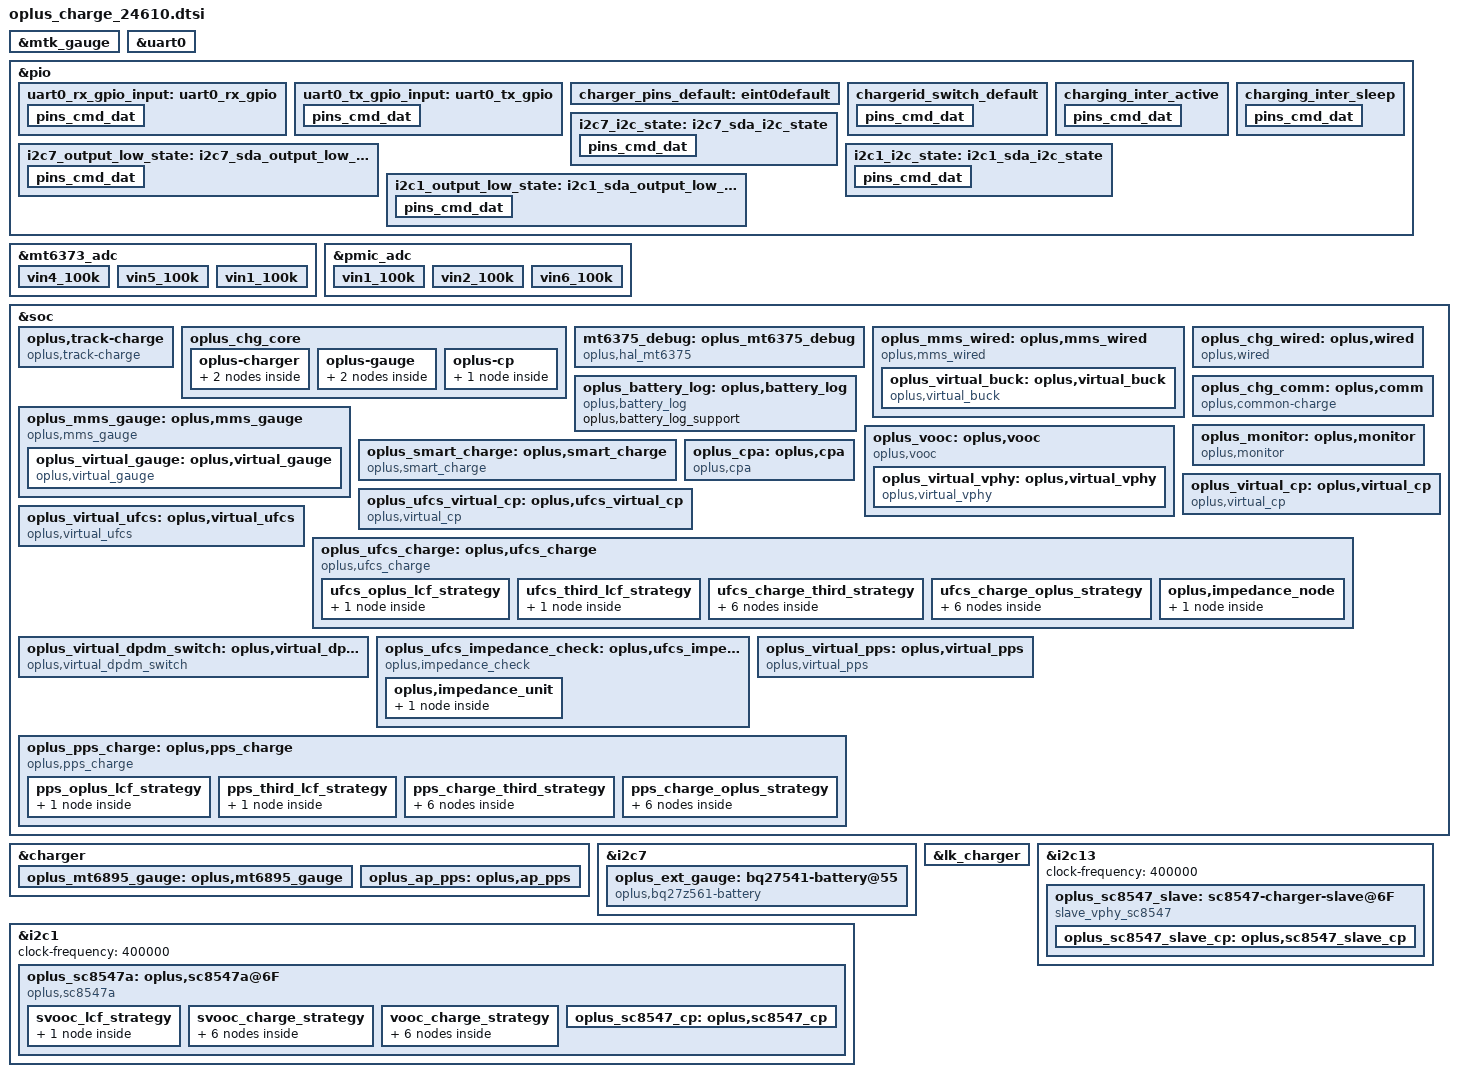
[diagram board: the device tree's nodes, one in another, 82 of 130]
// SPDX-License-Identifier: GPL-2.0-only
/*
* Copyright (C) 2021-2020 Oplus. All rights reserved.
*/
#include <dt-bindings/iio/mt635x-auxadc.h>
#include <dt-bindings/pinctrl/mt6373-pinfunc.h>
#include <dt-bindings/pinctrl/mt65xx.h>
//#include "oplus_charge_24610.h"
#include "oplus_chg.h"

/* charge start */
//&regulator_vibrator{
//	status = "disabled";
//};

&mtk_gauge {
	disable-mtkbattery = <(1)>;
	charger = <&mt6375_chg>;
};

&uart0 {
	pinctrl-names = "uart0_rx_gpio", "uart0_tx_gpio";
	pinctrl-0 = <&uart0_rx_gpio_input>;
	pinctrl-1 = <&uart0_tx_gpio_input>;
	status = "okay";

	txpin = <203>;
	rxpin = <204>;
};

&pio {
	uart0_rx_gpio_input: uart0_rx_gpio {
		pins_cmd_dat {
			pinmux = <PINMUX_GPIO204__FUNC_GPIO204>;
			input-enable;
			bias-disable;
		};
	};

	uart0_tx_gpio_input: uart0_tx_gpio {
		pins_cmd_dat {
			pinmux = <PINMUX_GPIO203__FUNC_GPIO203>;
			input-enable;
			bias-disable;
		};
	};
};

/* mt6373_adc is defined in mt6373.dtsi */
&mt6373_adc {
	vin4_100k {
		channel = <AUXADC_VIN4>;
		pures = <ADC_PURES_100K>;
	};
	vin5_100k {
		channel = <AUXADC_VIN5>;
		pures = <ADC_PURES_100K>;
	};
	vin1_100k {
		channel = <AUXADC_VIN1>;
		pures = <ADC_PURES_100K>;
	};
};

/* pmic_adc is defined in mt6363.dtsi */
&pmic_adc {
	vin1_100k {
		channel = <AUXADC_VIN1>;
		pures = <ADC_PURES_100K>;
	};
	vin2_100k {
		channel = <AUXADC_VIN2>;
		pures = <ADC_PURES_100K>;
	};
	vin6_100k {
		channel = <AUXADC_VIN6>;
		pures = <ADC_PURES_100K>;
	};
};

&soc {
	oplus,track-charge {
		compatible = "oplus,track-charge";
		track,fast_chg_break_t_thd = <1400>;
		track,general_chg_break_t_thd = <300>;
		track,voocphy_type = <TRACK_AP_SINGLE_CP_VOOCPHY>;
		track,wired_max_power = <100000>;
		track,wired_fast_chg_scheme = <0>;
	};

};

&pio {
	charger_pins_default: eint0default {
	};

	chargerid_switch_default: chargerid_switch_default {
		pins_cmd_dat {
			pinmux = <PINMUX_GPIO81__FUNC_GPIO81>;
			bias-disable;
		};
	};

	charging_inter_active: charging_inter_active {
		pins_cmd_dat {
			pinmux = <PINMUX_GPIO83__FUNC_GPIO83>;
			input-enable;
			bias-pull-up;
		};
	};

	charging_inter_sleep: charging_inter_sleep {
		pins_cmd_dat {
			pinmux = <PINMUX_GPIO83__FUNC_GPIO83>;
			input-enable;
			bias-pull-up;
		};
	};
};

&soc {
	oplus_chg_core {
		oplus,chg_framework_v2;
		oplus,smart_charging_screenoff;
		oplus,chg_spec_version = <OPLUS_CHG_SPEC_VER_V3P7>;

		oplus-charger {
			mtk_6895_groups: oplus,mtk_6895-groups {
				functions = <
					OPLUS_IC_FUNC_INIT
					OPLUS_IC_FUNC_EXIT
					OPLUS_IC_FUNC_REG_DUMP
					OPLUS_IC_FUNC_SMT_TEST
					OPLUS_IC_FUNC_BUCK_INPUT_PRESENT
					OPLUS_IC_FUNC_BUCK_INPUT_SUSPEND
					OPLUS_IC_FUNC_BUCK_INPUT_IS_SUSPEND
					OPLUS_IC_FUNC_BUCK_OUTPUT_SUSPEND
					OPLUS_IC_FUNC_BUCK_OUTPUT_IS_SUSPEND
					OPLUS_IC_FUNC_BUCK_SET_ICL
					OPLUS_IC_FUNC_BUCK_GET_ICL
					OPLUS_IC_FUNC_BUCK_SET_FCC
					OPLUS_IC_FUNC_BUCK_SET_FV
					OPLUS_IC_FUNC_BUCK_SET_ITERM
					OPLUS_IC_FUNC_BUCK_GET_INPUT_CURR
					OPLUS_IC_FUNC_BUCK_GET_INPUT_VOL
					OPLUS_IC_FUNC_OTG_BOOST_ENABLE
					OPLUS_IC_FUNC_BUCK_GET_CC_ORIENTATION
					OPLUS_IC_FUNC_BUCK_GET_CHARGER_TYPE
					OPLUS_IC_FUNC_BUCK_RERUN_BC12
					OPLUS_IC_FUNC_BUCK_QC_DETECT_ENABLE
					OPLUS_IC_FUNC_BUCK_SET_QC_CONFIG
					OPLUS_IC_FUNC_BUCK_SET_PD_CONFIG
					OPLUS_IC_FUNC_GET_SHUTDOWN_SOC
					OPLUS_IC_FUNC_BACKUP_SOC
					OPLUS_IC_FUNC_GET_TYPEC_MODE
					OPLUS_IC_FUNC_SET_TYPEC_MODE
					OPLUS_IC_FUNC_GET_TYPEC_ROLE
					OPLUS_IC_FUNC_GET_OTG_ENABLE
					OPLUS_IC_FUNC_BUCK_GET_HW_DETECT
					OPLUS_IC_FUNC_SET_USB_DISCHG_ENABLE
					OPLUS_IC_FUNC_GET_USB_DISCHG_STATUS
					OPLUS_IC_FUNC_IS_OPLUS_SVID
					OPLUS_IC_FUNC_BUCK_GET_USB_BTB_TEMP
					OPLUS_IC_FUNC_BUCK_GET_BATT_BTB_TEMP
					OPLUS_IC_FUNC_BUCK_SHIPMODE_ENABLE
					OPLUS_IC_FUNC_BUCK_SET_AICL_POINT
					OPLUS_IC_FUNC_SET_OTG_BOOST_CURR_LIMIT
					OPLUS_IC_FUNC_BUCK_GET_FV
					OPLUS_IC_FUNC_BUCK_GET_TYPEC_STATE
				>;
				virqs = <
					OPLUS_IC_VIRQ_ERR
					OPLUS_IC_VIRQ_CC_DETECT
					OPLUS_IC_VIRQ_PLUGIN
					OPLUS_IC_VIRQ_CC_CHANGED
					OPLUS_IC_VIRQ_CHG_TYPE_CHANGE
					OPLUS_IC_VIRQ_OTG_ENABLE
					OPLUS_IC_VIRQ_SVID
					OPLUS_IC_VIRQ_TYPEC_STATE
				>;
			};


			mt6375_debug_groups: oplus,mt6375_debug_groups {
				functions = <
					OPLUS_IC_FUNC_INIT
					OPLUS_IC_FUNC_EXIT
				>;
				virqs = <
					OPLUS_IC_VIRQ_ERR
				>;
			};
		};

		oplus-gauge {
			bq27541_groups: oplus,bq27541_groups {
				functions = <
					OPLUS_IC_FUNC_INIT
					OPLUS_IC_FUNC_EXIT
					OPLUS_IC_FUNC_REG_DUMP
					OPLUS_IC_FUNC_SMT_TEST
					OPLUS_IC_FUNC_GAUGE_GET_BATT_VOL
					OPLUS_IC_FUNC_GAUGE_GET_BATT_MAX
					OPLUS_IC_FUNC_GAUGE_GET_BATT_MIN
					OPLUS_IC_FUNC_GAUGE_GET_BATT_CURR
					OPLUS_IC_FUNC_GAUGE_GET_BATT_TEMP
					OPLUS_IC_FUNC_GAUGE_GET_BATT_SOC
					OPLUS_IC_FUNC_GAUGE_GET_BATT_FCC
					OPLUS_IC_FUNC_GAUGE_GET_BATT_CC
					OPLUS_IC_FUNC_GAUGE_GET_BATT_RM
					OPLUS_IC_FUNC_GAUGE_GET_BATT_SOH
					OPLUS_IC_FUNC_GAUGE_GET_BATT_AUTH
					OPLUS_IC_FUNC_GAUGE_GET_BATT_HMAC
					OPLUS_IC_FUNC_GAUGE_SET_BATT_FULL
					OPLUS_IC_FUNC_GAUGE_UPDATE_DOD0
					OPLUS_IC_FUNC_GAUGE_UPDATE_SOC_SMOOTH
					OPLUS_IC_FUNC_GAUGE_GET_CB_STATUS
					OPLUS_IC_FUNC_GAUGE_GET_BATT_NUM
					OPLUS_IC_FUNC_GAUGE_GET_DEVICE_TYPE
					OPLUS_IC_FUNC_GAUGE_GET_DEVICE_TYPE_FOR_VOOC
					OPLUS_IC_FUNC_GAUGE_GET_BATT_FCC
					OPLUS_IC_FUNC_GAUGE_GET_BATT_FC
					OPLUS_IC_FUNC_GAUGE_GET_BATT_QM
					OPLUS_IC_FUNC_GAUGE_GET_BATT_PD
					OPLUS_IC_FUNC_GAUGE_GET_BATT_RCU
					OPLUS_IC_FUNC_GAUGE_GET_BATT_RCF
					OPLUS_IC_FUNC_GAUGE_GET_BATT_FCU
					OPLUS_IC_FUNC_GAUGE_GET_BATT_FCF
					OPLUS_IC_FUNC_GAUGE_GET_BATT_SOU
					OPLUS_IC_FUNC_GAUGE_GET_BATT_DO0
					OPLUS_IC_FUNC_GAUGE_GET_BATT_DOE
					OPLUS_IC_FUNC_GAUGE_GET_BATT_TRM
					OPLUS_IC_FUNC_GAUGE_GET_BATT_PC
					OPLUS_IC_FUNC_GAUGE_GET_BATT_QS
					OPLUS_IC_FUNC_GAUGE_IS_SUSPEND
					OPLUS_IC_FUNC_GAUGE_GET_BCC_PARMS
					OPLUS_IC_FUNC_GAUGE_FASTCHG_UPDATE_BCC_PARMS
					OPLUS_IC_FUNC_GAUGE_GET_PREV_BCC_PARMS
					OPLUS_IC_FUNC_GAUGE_SET_BCC_PARMS
					OPLUS_IC_FUNC_GAUGE_SET_PROTECT_CHECK
					OPLUS_IC_FUNC_GAUGE_GET_AFI_UPDATE_DONE
					OPLUS_IC_FUNC_GAUGE_CHECK_RESET
					OPLUS_IC_FUNC_GAUGE_SET_RESET
					OPLUS_IC_FUNC_GAUGE_GET_DEVICE_TYPE_FOR_BCC
					OPLUS_IC_FUNC_GAUGE_GET_DOD0
					OPLUS_IC_FUNC_GAUGE_GET_DOD0_PASSED_Q
					OPLUS_IC_FUNC_GAUGE_GET_QMAX
					OPLUS_IC_FUNC_GAUGE_GET_QMAX_PASSED_Q
					OPLUS_IC_FUNC_GAUGE_GET_REG_INFO
					OPLUS_IC_FUNC_GAUGE_GET_CALIB_TIME
				>;
				virqs = <
					OPLUS_IC_VIRQ_ERR
					OPLUS_IC_VIRQ_OFFLINE
					OPLUS_IC_VIRQ_RESUME
				>;
			};

			mt6895_gauge_groups: oplus,mt6895_gauge_groups {
				functions = <
					OPLUS_IC_FUNC_INIT
					OPLUS_IC_FUNC_EXIT
					OPLUS_IC_FUNC_GAUGE_GET_SUBBOARD_TEMP
				>;
				virqs = <
					OPLUS_IC_VIRQ_ERR
				>;
			};
		};

		oplus-cp {
			sc8547_cp_groups: oplus,cp_groups {
			functions = <
					OPLUS_IC_FUNC_INIT
					OPLUS_IC_FUNC_EXIT
					OPLUS_IC_FUNC_REG_DUMP
					OPLUS_IC_FUNC_SMT_TEST
					OPLUS_IC_FUNC_CP_ENABLE
					OPLUS_IC_FUNC_CP_HW_INTI
					OPLUS_IC_FUNC_CP_SET_WORK_START
					OPLUS_IC_FUNC_CP_CHECK_WORK_MODE_SUPPORT
					OPLUS_IC_FUNC_CP_SET_WORK_MODE
					OPLUS_IC_FUNC_CP_GET_WORK_MODE
					OPLUS_IC_FUNC_CP_GET_VIN
					OPLUS_IC_FUNC_CP_GET_IIN
					OPLUS_IC_FUNC_CP_SET_IIN
					OPLUS_IC_FUNC_CP_GET_VOUT
					OPLUS_IC_FUNC_CP_GET_IOUT
					OPLUS_IC_FUNC_CP_GET_VAC
					OPLUS_IC_FUNC_CP_GET_WORK_STATUS
					OPLUS_IC_FUNC_CP_SET_ADC_ENABLE
					OPLUS_IC_FUNC_CP_WATCHDOG_ENABLE
				>;
				virqs = <
					OPLUS_IC_VIRQ_ERR
					OPLUS_IC_VIRQ_ONLINE
					OPLUS_IC_VIRQ_OFFLINE
				>;
			};
		};
	};
};

&soc {
	mt6375_debug: oplus_mt6375_debug {
		status = "okay";
		compatible = "oplus,hal_mt6375";

		oplus,tcpc_name = "type_c_port0";

		oplus,ic_type = <OPLUS_CHG_IC_BUCK>;
		oplus,ic_index = <2>;
	};
};

&charger {
	io-channels = <&mt6373_adc AUXADC_VIN1>,
			<&pmic_adc (ADC_PURES_100K_MASK | AUXADC_VIN1)>,
			<&pmic_adc (ADC_PURES_100K_MASK | AUXADC_VIN2)>,
			<&pmic_adc (ADC_PURES_100K_MASK | AUXADC_VIN6)>;
	io-channel-names = "auxadc5-chargeric_temp", "auxadc1-ntc_sub_bat_tem",
			   "auxadc5_batt_btb_temp", "auxadc6_usb_btb_temp";

	pinctrl-names = "default";
	pinctrl-0 = <&charger_pins_default>;
	oplus,support_ntc_01c_precision;
	oplus,support_subboard_ntc;
	max_charger_voltage = <15000000>;

	/* usbtemp dischg use pmic regulator to set vbus down */
	oplus,support_usbtemp_dischg_reg_configurable;
	oplus,usbtemp_dischg_reg_addr = <0x989>;
	oplus,usbtemp_dischg_reg_mask = <0x7>;
	oplus,usbtemp_dischg_enable = <0x2>;
	oplus,usbtemp_dischg_disable = <0x0>;

	oplus,ic_type = <OPLUS_CHG_IC_BUCK>;
	oplus,ic_index = <0>;

	oplus_mt6895_gauge: oplus,mt6895_gauge {
		oplus,ic_type = <OPLUS_CHG_IC_GAUGE>;
		oplus,ic_index = <1>;
	};
};
&i2c7 {
	status = "okay";
	clock-frequency = <100000>;

	oplus_ext_gauge: bq27541-battery@55 {
		status = "okay";
		compatible = "oplus,bq27z561-battery";
		reg = <0x55>;
		qcom,modify-soc-smooth;
		qcom,modify-soc-calibration;
		oplus,support_extern_cmd;
		oplus,batt_num = <1>;
		oplus,ic_type = <OPLUS_CHG_IC_GAUGE>;
		oplus,ic_index = <0>;
	};
};
&lk_charger {
	single_batt_external_gauge_support;
	is_support_mt6375;
	support_battery_type = <8>;
	support_tuv_authentication;
	support_sdp_screenoff;
	use_extern_gauge;
	high-temp-scheme;
	sub_board_temp_support;
	over_high_temp_thr = <60>;
	sub_board_adc_channel = <18>; /* AUXADC_VIN1 */
	sub_board_adc_pull_up_voltage = <1840>;

	support_quickboot_charge;

	/* mt6989 start */
	led-brightness = <102>;
	/* mt6989, such as max_charger_voltage to max-charger-voltage */
	max-charger-voltage = <15000000>;
	boot-battery-voltage = <3350000>;
	usb-charger-current = <500000>;
	ac-charger-current = <2050000>;
	ac-charger-input-current = <1500000>;
	non-std-ac-charger-current = <750000>;
	charging-host-charger-current = <1500000>;
	ta-ac-charger-current = <1500000>;
	pd-charger-current = <500000>;
	/* mt6989 end */
};

&i2c7 {
	pinctrl-names = "i2c-state", "output-low-state";
	pinctrl-0 = <&i2c7_i2c_state>;
	pinctrl-1 = <&i2c7_output_low_state>;
};
&pio {
	i2c7_i2c_state: i2c7_sda_i2c_state {
		pins_cmd_dat {
			pinmux = <PINMUX_GPIO120__FUNC_SCL7>,
			<PINMUX_GPIO121__FUNC_SDA7>;
			bias-pull-up;
		};
	};
	i2c7_output_low_state: i2c7_sda_output_low_state {
		pins_cmd_dat {
			pinmux = <PINMUX_GPIO120__FUNC_GPIO120>,
			<PINMUX_GPIO121__FUNC_GPIO121>;
			output-low;
		};
	};
};

&soc {
	oplus_mms_wired: oplus,mms_wired {
		compatible = "oplus,mms_wired";
		oplus,buck_ic = <&oplus_virtual_buck>;
		oplus,voocphy_ic = <&oplus_virtual_vphy>;

		oplus,adc_info_name = "100k_1840mv";
		oplus_spec,usbtemp_batttemp_gap = <12>;

		/* support for V2.0 usbtemp protect. */
		oplus,support_usbtemp_protect_v2;
		oplus_spec,usbtemp_batt_temp_low = <50>;
		oplus_spec,usbtemp_batt_temp_high = <50>;
		oplus_spec,usbtemp_batt_temp_over_hot = <60>;
		oplus_spec,usbtemp_ntc_temp_low = <57>;
		oplus_spec,usbtemp_ntc_temp_high = <69>;
		oplus_spec,usbtemp_temp_gap_low_with_batt_temp = <7>;
		oplus_spec,usbtemp_temp_gap_with_batt_temp_in_over_hot = <15>;
		oplus_spec,usbtemp_temp_gap_high_with_batt_temp = <12>;
		oplus_spec,usbtemp_temp_gap_low_without_batt_temp = <12>;
		oplus_spec,usbtemp_temp_gap_high_without_batt_temp = <24>;
		oplus_spec.usbtemp_rise_fast_temp_low = <3>;
		oplus_spec.usbtemp_rise_fast_temp_high = <3>;
		oplus_spec.usbtemp_rise_fast_temp_count_low = <30>;
		oplus_spec.usbtemp_rise_fast_temp_count_high = <20>;
		oplus_spec,usbtemp_cool_down_ntc_low = <54>;
		oplus_spec,usbtemp_cool_down_ntc_high = <65>;
		oplus_spec,usbtemp_cool_down_gap_low = <12>;
		oplus_spec,usbtemp_cool_down_gap_high = <20>;
		oplus_spec,usbtemp_cool_down_recover_ntc_low = <48>;
		oplus_spec,usbtemp_cool_down_recover_ntc_high = <60>;
		oplus_spec,usbtemp_cool_down_recover_gap_low = <6>;
		oplus_spec,usbtemp_cool_down_recover_gap_high = <15>;
		oplus_spec,usbtemp_otg_cc_boot_current_limit = <1300000>;

		oplus_virtual_buck: oplus,virtual_buck {
			compatible = "oplus,virtual_buck";
			oplus,buck_ic = <&charger &mt6375_debug>;
			oplus,buck_ic_index = <0 1>;
			oplus,buck_ic_current_ratio = <100 0>;
			oplus,buck_ic_connect = <OPLUS_CHG_IC_CONNECT_PARALLEL>;
			oplus,main_charger = <0>;
			oplus,buck_ic_func_group = <&mtk_6895_groups &mt6375_debug_groups>;

			oplus,ic_type = <OPLUS_CHG_IC_VIRTUAL_BUCK>;
			oplus,ic_index = <0>;

			io-channels = <&mt6373_adc AUXADC_VIN4>, <&mt6373_adc AUXADC_VIN5>;
			io-channel-names = "usb_temp_adc_l", "usb_temp_adc_r";

			oplus,uart_tx-gpio = <&pio 203 0x00>;
			oplus,uart_rx-gpio = <&pio 204 0x00>;
		};
	};

	oplus_mms_gauge: oplus,mms_gauge {
		compatible = "oplus,mms_gauge";
		oplus,gauge_ic = <&oplus_virtual_gauge>;
		oplus,topic-update-interval = <10000>;
		oplus,support_subboard_ntc;

		oplus_virtual_gauge: oplus,virtual_gauge {
			compatible = "oplus,virtual_gauge";
			oplus,gauge_ic = <&oplus_ext_gauge &oplus_mt6895_gauge>;
			oplus,gauge_ic_index = <0 1>;
			oplus,gauge_ic_func_group = <&bq27541_groups &mt6895_gauge_groups>;
			oplus,batt_capacity_mah = <7000>;
			oplus,ic_type = <OPLUS_CHG_IC_VIRTUAL_GAUGE>;
			oplus,ic_index = <0>;
		};
	};
};

&soc {
	oplus_battery_log: oplus,battery_log {
		compatible = "oplus,battery_log";

		oplus,battery_log_support;
	};

	oplus_chg_wired: oplus,wired {
		compatible = "oplus,wired";

		oplus,vooc-support;

		oplus_spec,vbatt_pdqc_to_5v_thr = <4500>;
		oplus_spec,vbatt_pdqc_to_9v_thr = <4500>;
		oplus_spec,pd-iclmax-ma = <2000>;
		oplus_spec,qc-iclmax-ma = <2000>;
		oplus_spec,non-standard-ibatmax-ma = <500>;
		oplus_spec,input-power-mw = <
			2500		/* OPLUS_WIRED_CHG_MODE_UNKNOWN */
			2500		/* OPLUS_WIRED_CHG_MODE_SDP */
			7500		/* OPLUS_WIRED_CHG_MODE_CDP */
			10000		/* OPLUS_WIRED_CHG_MODE_DCP */
			15000		/* OPLUS_WIRED_CHG_MODE_VOOC */
			13500		/* OPLUS_WIRED_CHG_MODE_QC */
			13500		/* OPLUS_WIRED_CHG_MODE_PD */
		>;
		oplus_spec,led_on-fccmax-ma = <0 1850 3083 3300 3300 3300 3300 1000 0>;
		oplus_spec,fccmax-ma-lv = <
			0 1850 2200 2200 2200 2200 2200 2200 0	/* OPLUS_WIRED_CHG_MODE_UNKNOWN */
			0 600  600  600  600  600  600  600  0	/* OPLUS_WIRED_CHG_MODE_SDP */
			0 1600 1600 1600 1600 1600 1600 1600 0	/* OPLUS_WIRED_CHG_MODE_CDP */
			0 1850 2200 2200 2200 2200 2200 2200 0	/* OPLUS_WIRED_CHG_MODE_DCP */
			0 1850 2200 2200 2200 2200 2200 2200 0	/* OPLUS_WIRED_CHG_MODE_VOOC */
			0 1850 3083 3300 3300 3300 3300 3300 0	/* OPLUS_WIRED_CHG_MODE_QC */
			0 1850 3083 3300 3300 3300 3300 3300 0	/* OPLUS_WIRED_CHG_MODE_PD */
		>;
		oplus_spec,fccmax-ma-hv = <
			0 617  1233 1600 1600 1600 1600 1600 0	/* OPLUS_WIRED_CHG_MODE_UNKNOWN */
			0 600  600  600  600  600  600  600  0	/* OPLUS_WIRED_CHG_MODE_SDP */
			0 617  1233 1600 1600 1600 1600 1600 0	/* OPLUS_WIRED_CHG_MODE_CDP */
			0 617  1233 1850 2200 2200 2200 2200 0	/* OPLUS_WIRED_CHG_MODE_DCP */
			0 617  1233 1850 2200 2200 2200 2200 0	/* OPLUS_WIRED_CHG_MODE_VOOC */
			0 617  1233 1850 3083 3300 3300 3300 0	/* OPLUS_WIRED_CHG_MODE_QC */
			0 617  1233 1850 3083 3300 3300 3300 0	/* OPLUS_WIRED_CHG_MODE_PD */
		>;
                oplus_spec,cool_down_sale_pdqc_vol_mv = <5000>;
                oplus_spec,cool_down_sale_pdqc_curr_ma = <1200>;
                oplus_spec,cool_down_pdqc_vol_mv = <5000 5000 5000 9000 9000>;
                oplus_spec,cool_down_pdqc_curr_ma = <1200 1500 2000 1500 2000>;
		oplus_spec,cool_down_vooc_curr_ma = <1200 1500 2000 2500 3000 3000>;
		oplus_spec,cool_down_normal_curr_ma = <1200 1500 2000>;

		oplus_spec,vbus_ov_thr_mv = <11000 11000>;
		oplus_spec,vbus_uv_thr_mv = <4300 4300>;

		/* first data is strategy used temp type */
		oplus,vooc_strategy_name = "cgcl";
		oplus,vooc_strategy_data = <OPLUS_STRATEGY_USE_BATT_TEMP
					    0   350 3600 1 0
					    330 370 3200 2 0
					    350 440 2200 2 1>;
	};

	oplus_chg_comm: oplus,comm {
		compatible = "oplus,common-charge";
		oplus_spec,batt-them-thr = <(-100) 0 50 120 160 350 450 530>;
		oplus_spec,iterm-ma = <353>; /* 7000*0.05+10 */
		oplus_spec,removed_bat_decidegc = <390>; /*-39 degree*/
		oplus_spec,fv-mv = <4500 4500 4500 4500 4500 4500 4475 4130 4130>;
		oplus_spec,sw-fv-mv = <4450 4450 4450 4450 4450 4450 4425 4080 4080>;
		oplus_spec,hw-fv-inc-mv = <0 18 18 18 18 18 18 18 0>;
		oplus_spec,sw-over-fv-mv = <4510 4510 4510 4510 4510 4510 4485 4140 4140>;
		oplus_spec,sw-over-fv-dec-mv = <8>;
		oplus_spec,non-standard-sw-fv-mv = <3930>;
		oplus_spec,non-standard-fv-mv = <3980>;
		oplus_spec,non-standard-hw-fv-inc-mv = <18>;
		oplus_spec,non-standard-sw-over-fv-mv = <3990>;
		oplus_spec,non-standard-vbatdet-mv = <3680>;
		oplus_spec,wired-vbatdet-mv = <0 4200 4300 4400 4400 4400 4375 4030 0>;
		oplus_spec,fcc-gear-thr-mv = <4180>;
		oplus_spec,fcc-gear-shake-mv = <550 550 350 200 200 150 150 100 100>;
		oplus_spec,vbatt-ov-thr-mv = <4600>;

		oplus_spec,full_pre_ffc_judge;
		oplus_spec,full-pre-ffc-mv = <4495>;
		oplus_spec,ffc-temp-thr = <120 210 350 440>;
		oplus_spec,wired-ffc-step-max = <2>;
		oplus_spec,wired-ffc-fv-mv = <4630 4630>;

		oplus_spec,wired-ffc-fv-cutoff-mv = <4565 4565 4520
						     4565 4565 4495>;
		oplus_spec,wired-ffc-fcc-ma = <2000 2000 1500
					       1900 1900 1000>;
		oplus_spec,wired-ffc-fcc-cutoff-ma = <1800 1800 1300
						      1800 1800 900>;
		/* 2s battery */
		oplus_spec,wired-aging-ffc-version = <AGING_FFC_V1>;
		oplus_spec,wired-aging-ffc-offset-mv = <10 15
						 10 15>;
		oplus_spec,wired-aging-ffc-cycle-thr = <500 1000>;
		oplus_spec,wls-ffc-step-max = <2>;
		oplus_spec,wls-ffc-fv-mv = <4630 4630>;
		oplus_spec,wls-ffc-fv-cutoff-mv = <4565 4565 4520
						     4565 4565 4495>;
		oplus_spec,wls-ffc-icl-ma = <1150 1150 1550
					     750 950 1450>;
		oplus_spec,wls-ffc-fcc-ma = <2000 2000 1500
					       1900 1900 1000>;
		oplus_spec,wls-ffc-fcc-cutoff-ma = <1800 1800 1300
						      1800 1800 900>;
		oplus_spec,vbat_uv_thr_mv = <3000>;
		oplus_spec,vbat_charging_uv_thr_mv = <2900>;

		/*If use subboard NTC as battery temp, config it as 20, otherwise 0 */
		oplus_spec,tbatt_power_off_cali_temp = <0>;
		oplus,vooc_show_ui_soc_decimal;
		oplus_spec,poweroff_high_batt_temp = <720>;
		oplus_spec,poweroff_emergency_batt_temp = <770>;
		oplus,ui_soc_decimal_speedmin = <20>;
		oplus,gauge_stuck_jump_support;
		oplus,gauge_stuck_threshold = <15>;
		oplus,gauge_stuck_time = <50>;

		oplus,hidden_soc_switch;
		oplus,reserve_chg_soc = <3>;
		oplus,hidden_soc_percent = <20>;
	};

	oplus_monitor: oplus,monitor {
		compatible = "oplus,monitor";
		oplus,topic-update-interval = <60000>;

		track,fast_chg_break_t_thd = <1400>;
		track,general_chg_break_t_thd = <300>;
		track,voocphy_type = <TRACK_AP_DUAL_CP_VOOCPHY>;
		track,wired_max_power = <80000>;
		track,wired_fast_chg_scheme = <2>;

		track,gauge_status_ctrl;
		track,external_gauge_num = <1>;

		oplus,chg_into_liquid;
		oplus,chg_into_liquid_cc_disconnect = <10>;
		oplus,chg_into_liquid_total_time = <5000>;
		oplus,chg_into_liquid_max_interval_time = <700>;
	};

	oplus_vooc: oplus,vooc {
		compatible = "oplus,vooc";
		oplus,vooc_ic = <&oplus_virtual_vphy>;

		oplus_spec,vooc_soc_range = <50 75 85>;

		oplus,vooc_data_width = <7>;
		oplus,vooc_curr_max = <CP_CURR_LIMIT_7BIT_15_0A>; /* 80W: 11V 7.3A(IBUS *2) */
		oplus,vooc_project = <7>;
		oplus,vooc_curr_table_type = <VOOC_CP_CURR_TABLE>;
		oplus,vooc_power_max_w = <80>;
		oplus,voocphy_support = <3>;
		oplus,support_fake_vooc_check; /* AP_DUAL_CP_VOOCPHY */

	//	oplus,smart_chg_bcc_support;
		oplus,subboard_ntc_abnormal_current = <4000>;

		oplus,abnormal_adapter_current = <CP_CURR_LIMIT_7BIT_15_0A CP_CURR_LIMIT_7BIT_15_0A
						CP_CURR_LIMIT_7BIT_10_0A CP_CURR_LIMIT_7BIT_10_0A
						CP_CURR_LIMIT_7BIT_8_0A CP_CURR_LIMIT_7BIT_8_0A
						CP_CURR_LIMIT_7BIT_6_0A CP_CURR_LIMIT_7BIT_6_0A
						CP_CURR_LIMIT_7BIT_4_0A CP_CURR_LIMIT_7BIT_4_0A>;

		oplus,abnormal_over_80w_adapter_current = <CP_CURR_LIMIT_7BIT_15_0A CP_CURR_LIMIT_7BIT_15_0A
						CP_CURR_LIMIT_7BIT_14_0A CP_CURR_LIMIT_7BIT_14_0A
						CP_CURR_LIMIT_7BIT_12_0A CP_CURR_LIMIT_7BIT_12_0A
						CP_CURR_LIMIT_7BIT_10_0A CP_CURR_LIMIT_7BIT_10_0A
						CP_CURR_LIMIT_7BIT_8_0A CP_CURR_LIMIT_7BIT_8_0A
						CP_CURR_LIMIT_7BIT_6_0A CP_CURR_LIMIT_7BIT_6_0A
						CP_CURR_LIMIT_7BIT_4_0A CP_CURR_LIMIT_7BIT_4_0A>;

		/* first data is strategy used temp type */
		oplus,general_strategy_name = "cgcl";
		oplus,general_strategy_data = < OPLUS_STRATEGY_USE_SHELL_TEMP
						0   385 CP_CURR_LIMIT_7BIT_15_0A 1 0
						380 390 CP_CURR_LIMIT_7BIT_8_0A 2 0
						390 410 CP_CURR_LIMIT_7BIT_6_0A 3 1
						410 430 CP_CURR_LIMIT_7BIT_4_0A 3 2 >;


	oplus_virtual_vphy: oplus,virtual_vphy {
			compatible = "oplus,virtual_vphy";
			oplus,vphy_ic = <&oplus_sc8547a>;
			oplus,dpdm_switch_ic = <&oplus_virtual_dpdm_switch>;

			oplus,ic_type = <OPLUS_CHG_IC_VIRTUAL_VPHY>;
			oplus,ic_index = <0>;
		};
	};
	oplus_smart_charge: oplus,smart_charge {
		compatible = "oplus,smart_charge";
		oplus,smart_chg_soh_support;
		oplus,quick_mode_gain_support;
	};

	oplus_cpa: oplus,cpa {
		compatible = "oplus,cpa";
		oplus,protocol_list = <CHG_PROTOCOL_UFCS 44
		                       CHG_PROTOCOL_VOOC 80
				       CHG_PROTOCOL_PPS  55
				       CHG_PROTOCOL_PD 18
				       CHG_PROTOCOL_QC 18>;
		oplus,default_protocol_list = <CHG_PROTOCOL_UFCS
					       CHG_PROTOCOL_VOOC
					       CHG_PROTOCOL_PPS
					       CHG_PROTOCOL_PD>;
	};

	oplus_virtual_cp: oplus,virtual_cp {
		compatible = "oplus,virtual_cp";

		oplus,ic_type = <OPLUS_CHG_IC_VIRTUAL_CP>;
		oplus,ic_index = <0>;

		oplus,cp_ic = <&oplus_sc8547_cp &oplus_sc8547_slave_cp>;
		oplus,input_curr_max_ma = <3000 3000>;

		oplus,cp_ic_connect = <OPLUS_CHG_IC_CONNECT_PARALLEL>;
		oplus,main_cp = <0>;
		oplus,reg_proc_node;
	};

	oplus_ufcs_virtual_cp: oplus,ufcs_virtual_cp {
		compatible = "oplus,virtual_cp";

		oplus,ic_type = <OPLUS_CHG_IC_VIRTUAL_CP>;
		oplus,ic_index = <1>;

		oplus,cp_ic = <&oplus_virtual_cp>;
		oplus,input_curr_max_ma = <9100>;

		oplus,cp_ic_connect = <OPLUS_CHG_IC_CONNECT_PARALLEL>;
		oplus,main_cp = <0>;
	};

	oplus_virtual_ufcs: oplus,virtual_ufcs {
		compatible = "oplus,virtual_ufcs";

		oplus,ic_type = <OPLUS_CHG_IC_VIRTUAL_UFCS>;
		oplus,ic_index = <0>;
	};

	oplus_ufcs_charge: oplus,ufcs_charge {
		compatible = "oplus,ufcs_charge";
		oplus,ufcs_ic = <&oplus_virtual_ufcs>;
		oplus,cp_ic = <&oplus_virtual_cp>;
		oplus,dpdm_switch_ic = <&oplus_virtual_dpdm_switch>;

		oplus,impedance_unit = <&oplus_ufcs_impedance_unit>;

		oplus,target_vbus_mv = <11000>;
		oplus,curr_max_ma = <4000>;
		oplus,curr_table_type = <UFCS_CURR_CP_TABLE>;
		oplus,ufcs_warm_allow_vol = <4000>;
		oplus,ufcs_warm_allow_soc = <55>;
		oplus,ufcs_strategy_normal_current = <4000>;
		oplus,ufcs_over_high_or_low_current = <4000>;
		oplus,ufcs_timeout_third = <17614>;
		oplus,ufcs_timeout_oplus = <10800>;
		oplus,ufcs_ibat_over_third = <9000>;
		oplus,ufcs_ibat_over_oplus = <9000>;
		oplus,ufcs_full_cool_sw_vbat = <4500>;
		oplus,ufcs_full_normal_sw_vbat = <4500>;
		oplus,ufcs_full_normal_hw_vbat = <4550>;
		oplus,ufcs_full_ffc_vbat = <4510>;
		oplus,ufcs_full_warm_vbat = <4130>;
		oplus,ufcs_full_cool_sw_vbat_third = <4500>;
		oplus,ufcs_full_normal_sw_vbat_third= <4500>;
		oplus,ufcs_full_normal_hw_vbat_third = <4550>;
		oplus,ufcs_current_change_timeout = <100>;
		oplus,ufcs_r_default = <90 60 60 60 60 60 60>;
		oplus,ufcs_rmos_mohm = <5>;
		oplus,ufcs_r_limit = <260 200 140 90 40>;
		oplus,ufcs_strategy_batt_high_temp = <385 420 425 375 415 420>;
		oplus,ufcs_strategy_high_current = <4000 2500 2000 4000 4000 2500>;
		oplus,ufcs_little_cool_high_temp = <210>;
		oplus,curve_strategy_name = "pps_ufcs_curve_v2";
		oplus_spec,ufcs_high_soc = <95>;
		oplus,ufcs_charge_strategy_soc = <0 20 35 55 75 85 95>;
		oplus,ufcs_charge_strategy_temp = <0 50 120 160 350 440 510>;

		ufcs_oplus_lcf_strategy {
			oplus,temp_type = <OPLUS_STRATEGY_USE_SHELL_TEMP>;
			oplus,temp_range = <0 50 120 160 210 380 430>;

			strategy_temp_range_curves {
				strategy_temp_range_t0 =	<420 4570 0
								 395 4565 0
								 370 4550 0
								 345 4540 0
								 320 4530 1>;
				strategy_temp_range_t1 =	<550 4570 0
								 515 4565 0
								 480 4550 0
								 445 4540 0
								 410 4530 1>;
				strategy_temp_range_t2 =	<700 4570 0
								 655 4565 0
								 610 4550 0
								 565 4540 0
								 520 4530 1>;
				strategy_temp_range_t3 =	<850 4570 0
								 800 4565 0
								 700 4550 0
								 600 4540 0
								 450 4530 1>;
				strategy_temp_range_t4 =	<1750 4575 0
								 1700 4570 0
								 1600 4555 0
								 1500 4545 0
								 1350 4535 1>;
				strategy_temp_range_t5 =	<2000 4570 0
								 1950 4565 0
								 1850 4550 0
								 1750 4540 0
								 1600 4530 1>;
			};
		};

		ufcs_third_lcf_strategy {
			oplus,temp_type = <OPLUS_STRATEGY_USE_SHELL_TEMP>;
			oplus,temp_range = <0 50 120 160 210 380 440>;

			strategy_temp_range_curves {
				strategy_temp_range_t0 =	<850 4550 0
								 800 4540 0
								 750 4530 0
								 700 4520 0
								 650 4510 1>;
				strategy_temp_range_t1 =	<750 4550 0
								 700 4540 0
								 650 4530 0
								 550 4520 0
								 450 4510 1>;
				strategy_temp_range_t2 =	<850 4550 0
								 805 4540 0
								 760 4530 0
								 715 4520 0
								 670 4510 1>;
				strategy_temp_range_t3 =	<900 4550 0
								 850 4540 0
								 750 4530 0
								 650 4520 0
								 500 4510 1>;
				strategy_temp_range_t4 =	<1250 4550 0
								 1200 4540 0
								 1100 4530 0
								 1000 4520 0
								 850 4510 1>;
				strategy_temp_range_t5 =	<1900 4550 0
								 1850 4540 0
								 1750 4530 0
								 1650 4520 0
								 1500 4510 1>;
			};
		};

		ufcs_charge_third_strategy {
			oplus,temp_type = <OPLUS_STRATEGY_USE_SHELL_TEMP>;
			oplus,soc_range = <0 20 35 55 75 85 95>;
			oplus,temp_range = <0 50 120 160 210 350 440 510>;

			strategy_soc_range_min {
				strategy_temp_little_cold =	<11000 4150 3950 0 0
								11000 4150 3500 0 0
								11000 4490 3250 0 0
								11000 4490 3000 0 0
								11000 4490 2550 0 0
								11000 4490 2500 0 0
								11000 4490 2000 0 0
								11000 4490 1500 0 0
								11000 4500 1000 1 0>;
				strategy_temp_cool =		<11000 4150 4000 0 0
								11000 4490 3950 0 0
								11000 4490 3500 0 0
								11000 4490 3000 0 0
								11000 4490 2550 0 0
								11000 4490 2500 0 0
								11000 4490 2000 0 0
								11000 4490 1500 0 0
								11000 4500 1000 1 0>;
				strategy_temp_little_cool =	<11000 4490 4000 0 0
								11000 4490 3500 0 0
								11000 4490 3000 0 0
								11000 4490 2500 0 0
								11000 4490 2000 0 0
								11000 4490 1500 0 0
								11000 4500 1000 1 0>;
				strategy_temp_little_cool_high =	<11000 4490 4000 0 0
								11000 4490 3500 0 0
								11000 4490 3000 0 0
								11000 4490 2500 0 0
								11000 4490 2000 0 0
								11000 4490 1500 0 0
								11000 4500 1000 1 0>;
				strategy_temp_normal_low =	<11000 4490 4000 0 0
								11000 4490 3500 0 0
								11000 4490 3000 0 0
								11000 4490 2500 0 0
								11000 4490 2000 0 0
								11000 4490 1500 0 0
								11000 4500 1000 1 0>;
				strategy_temp_normal_high =	<11000 4465 4000 0 0
								11000 4465 3500 0 0
								11000 4465 3000 0 0
								11000 4465 2500 0 0
								11000 4465 2000 0 0
								11000 4465 1500 0 0
								11000 4475 1000 1 0>;
				strategy_temp_warm =		<11000 4120 1850 0 0
								11000 4120 1500 0 0
								11000 4130 1000 1 0>;
			};
			strategy_soc_range_low {
				strategy_temp_little_cold =	<11000 4150 3950 0 0
								11000 4150 3500 0 0
								11000 4490 3250 0 0
								11000 4490 3000 0 0
								11000 4490 2550 0 0
								11000 4490 2500 0 0
								11000 4490 2000 0 0
								11000 4490 1500 0 0
								11000 4500 1000 1 0>;
				strategy_temp_cool =		<11000 4150 4000 0 0
								11000 4490 3950 0 0
								11000 4490 3500 0 0
								11000 4490 3000 0 0
								11000 4490 2550 0 0
								11000 4490 2500 0 0
								11000 4490 2000 0 0
								11000 4490 1500 0 0
								11000 4500 1000 1 0>;
				strategy_temp_little_cool =	<11000 4490 4000 0 0
								11000 4490 3500 0 0
								11000 4490 3000 0 0
								11000 4490 2500 0 0
								11000 4490 2000 0 0
								11000 4490 1500 0 0
								11000 4500 1000 1 0>;
				strategy_temp_little_cool_high =	<11000 4490 4000 0 0
								11000 4490 3500 0 0
								11000 4490 3000 0 0
								11000 4490 2500 0 0
								11000 4490 2000 0 0
								11000 4490 1500 0 0
								11000 4500 1000 1 0>;
				strategy_temp_normal_low =	<11000 4490 4000 0 0
								11000 4490 3500 0 0
								11000 4490 3000 0 0
								11000 4490 2500 0 0
								11000 4490 2000 0 0
								11000 4490 1500 0 0
								11000 4500 1000 1 0>;
				strategy_temp_normal_high =	<11000 4465 4000 0 0
								11000 4465 3500 0 0
								11000 4465 3000 0 0
								11000 4465 2500 0 0
								11000 4465 2000 0 0
								11000 4465 1500 0 0
								11000 4475 1000 1 0>;
				strategy_temp_warm =		<11000 4120 1850 0 0
								11000 4120 1500 0 0
								11000 4130 1000 1 0>;
			};
			strategy_soc_range_mid_low {
				strategy_temp_little_cold =	<11000 4490 2000 0 0
								11000 4490 1500 0 0
								11000 4500 1000 1 0>;
				strategy_temp_cool =		<11000 4490 2500 0 0
								11000 4490 2000 0 0
								11000 4490 1500 0 0
								11000 4500 1000 1 0>;
				strategy_temp_little_cool =	<11000 4490 4000 0 0
								11000 4490 3500 0 0
								11000 4490 3000 0 0
								11000 4490 2500 0 0
								11000 4490 2000 0 0
								11000 4490 1500 0 0
								11000 4500 1000 1 0>;
				strategy_temp_little_cool_high =	<11000 4490 4000 0 0
								11000 4490 3500 0 0
								11000 4490 3000 0 0
								11000 4490 2500 0 0
								11000 4490 2000 0 0
								11000 4490 1500 0 0
								11000 4500 1000 1 0>;
				strategy_temp_normal_low =	<11000 4490 4000 0 0
								11000 4490 3500 0 0
								11000 4490 3000 0 0
								11000 4490 2500 0 0
								11000 4490 2000 0 0
								11000 4490 1500 0 0
								11000 4500 1000 1 0>;
				strategy_temp_normal_high =	<11000 4465 4000 0 0
								11000 4465 3500 0 0
								11000 4465 3000 0 0
								11000 4465 2500 0 0
								11000 4465 2000 0 0
								11000 4465 1500 0 0
								11000 4475 1000 1 0>;
				strategy_temp_warm =		<11000 4120 1850 0 0
								11000 4120 1500 0 0
								11000 4130 1000 1 0>;
			};
			strategy_soc_range_mid {
				strategy_temp_little_cold =	<11000 4490 1500 0 0
								11000 4500 1000 1 0>;
				strategy_temp_cool =		<11000 4490 1500 0 0
								11000 4500 1000 1 0>;
				strategy_temp_little_cool =	<11000 4490 2000 0 0
								11000 4490 1500 0 0
								11000 4500 1000 1 0>;
				strategy_temp_little_cool_high =	<11000 4490 2000 0 0
								11000 4490 1500 0 0
								11000 4500 1000 1 0>;
				strategy_temp_normal_low =	<11000 4490 2000 0 0
								11000 4490 1500 0 0
								11000 4500 1000 1 0>;
				strategy_temp_normal_high =	<11000 4465 2500 0 0
								11000 4465 2000 0 0
								11000 4465 1500 0 0
								11000 4475 1000 1 0>;
				strategy_temp_warm =		<11000 4120 1850 0 0
								11000 4120 1500 0 0
								11000 4130 1000 1 0>;
			};
			strategy_soc_range_mid_high {
				strategy_temp_little_cold =	<11000 4500 1000 1 0>;
				strategy_temp_cool =		<11000 4500 1000 1 0>;
				strategy_temp_little_cool =	<11000 4490 1500 0 0
								11000 4500 1000 1 0>;
				strategy_temp_little_cool_high =	<11000 4490 1500 0 0
								11000 4500 1000 1 0>;
				strategy_temp_normal_low =	<11000 4490 1500 0 0
								11000 4500 1000 1 0>;
				strategy_temp_normal_high =	<11000 4465 1500 0 0
								11000 4475 1000 1 0>;
				strategy_temp_warm =		<11000 4120 1850 0 0
								11000 4120 1500 0 0
								11000 4130 1000 1 0>;
			};
			strategy_soc_range_high {
				strategy_temp_little_cold =	<11000 4500 1000 1 0>;
				strategy_temp_cool =		<11000 4500 1000 1 0>;
				strategy_temp_little_cool =	<11000 4500 1000 1 0>;
				strategy_temp_little_cool_high =	<11000 4500 1000 1 0>;
				strategy_temp_normal_low =	<11000 4500 1000 1 0>;
				strategy_temp_normal_high =	<11000 4475 1000 1 0>;
				strategy_temp_warm =		<11000 4130 1000 1 0>;
			};
		};

		ufcs_charge_oplus_strategy {
			oplus,temp_type = <OPLUS_STRATEGY_USE_SHELL_TEMP>;
			oplus,soc_range = <0 20 35 55 75 85 95>;
			oplus,temp_range = <0 50 120 160 210 350 440 510>;

			strategy_soc_range_min {
				strategy_temp_little_cold =	<11000 4140 1300 0 0
								11000 4150 1000 1 0>;
				strategy_temp_cool =		<11000 4150 2100 0 0
								11000 4150 2000 0 0
								11000 4150 1500 0 0
								11000 4490 1300 0 0
								11000 4490 1000 1 0>;
				strategy_temp_little_cool =	<11000 4150 2700 0 0
								11000 4150 2500 0 0
								11000 4330 2100 0 0
								11000 4330 2000 0 0
								11000 4330 1500 0 0
								11000 4490 1300 0 0
								11000 4500 1000 1 0>;
				strategy_temp_little_cool_high =	<11000 4230 4000 0 0
								11000 4230 3500 0 0
								11000 4490 3300 0 0
								11000 4490 3000 0 0
								11000 4490 2700 0 0
								11000 4490 2500 0 0
								11000 4490 2000 0 0
								11000 4490 1500 0 0
								11000 4500 1000 1 0>;
				strategy_temp_normal_low =	<11000 4280 4000 0 0
								11000 4430 3800 0 0
								11000 4430 3500 0 0
								11000 4490 3300 0 0
								11000 4490 3000 0 0
								11000 4490 2500 0 0
								11000 4490 2000 0 0
								11000 4490 1500 0 0
								11000 4500 1000 1 0>;
				strategy_temp_normal_high =	<11000 4280 4000 0 0
								11000 4430 3800 0 0
								11000 4430 3500 0 0
								11000 4475 3300 0 0
								11000 4475 3000 0 0
								11000 4475 2500 0 0
								11000 4475 2000 0 0
								11000 4475 1500 0 0
								11000 4485 1000 1 0>;
				strategy_temp_warm =		<11000 4120 1600 0 0
								11000 4120 1500 0 0
								11000 4130 1000 1 0>;
			};
			strategy_soc_range_low {
				strategy_temp_little_cold =	<11000 4140 1300 0 0
								11000 4150 1000 1 0>;
				strategy_temp_cool =		<11000 4150 2100 0 0
								11000 4150 2000 0 0
								11000 4150 1500 0 0
								11000 4490 1300 0 0
								11000 4490 1000 1 0>;
				strategy_temp_little_cool =	<11000 4150 2700 0 0
								11000 4150 2500 0 0
								11000 4330 2100 0 0
								11000 4330 2000 0 0
								11000 4330 1500 0 0
								11000 4490 1300 0 0
								11000 4500 1000 1 0>;
				strategy_temp_little_cool_high =	<11000 4230 4000 0 0
								11000 4230 3500 0 0
								11000 4490 3300 0 0
								11000 4490 3000 0 0
								11000 4490 2700 0 0
								11000 4490 2500 0 0
								11000 4490 2000 0 0
								11000 4490 1500 0 0
								11000 4500 1000 1 0>;
				strategy_temp_normal_low =	<11000 4280 4000 0 0
								11000 4430 3800 0 0
								11000 4430 3500 0 0
								11000 4490 3300 0 0
								11000 4490 3000 0 0
								11000 4490 2500 0 0
								11000 4490 2000 0 0
								11000 4490 1500 0 0
								11000 4500 1000 1 0>;
				strategy_temp_normal_high =	<11000 4280 4000 0 0
								11000 4430 3800 0 0
								11000 4430 3500 0 0
								11000 4475 3300 0 0
								11000 4475 3000 0 0
								11000 4475 2500 0 0
								11000 4475 2000 0 0
								11000 4475 1500 0 0
								11000 4485 1000 1 0>;
				strategy_temp_warm =		<11000 4120 1600 0 0
								11000 4120 1500 0 0
								11000 4130 1000 1 0>;
			};
			strategy_soc_range_mid_low {
				strategy_temp_little_cold =	<11000 4140 1300 0 0
								11000 4150 1000 1 0>;
				strategy_temp_cool =		<11000 4150 2100 0 0
								11000 4150 2000 0 0
								11000 4150 1500 0 0
								11000 4490 1300 0 0
								11000 4490 1000 1 0>;
				strategy_temp_little_cool =	<11000 4150 2700 0 0
								11000 4150 2500 0 0
								11000 4330 2100 0 0
								11000 4330 2000 0 0
								11000 4330 1500 0 0
								11000 4490 1300 0 0
								11000 4500 1000 1 0>;
				strategy_temp_little_cool_high =	<11000 4490 3000 0 0
								11000 4490 2800 0 0
								11000 4490 2500 0 0
								11000 4490 2000 0 0
								11000 4490 1500 0 0
								11000 4500 1000 1 0>;
				strategy_temp_normal_low =	<11000 4280 4000 0 0
								11000 4430 3800 0 0
								11000 4430 3500 0 0
								11000 4490 3300 0 0
								11000 4490 3000 0 0
								11000 4490 2500 0 0
								11000 4490 2000 0 0
								11000 4490 1500 0 0
								11000 4500 1000 1 0>;
				strategy_temp_normal_high =	<11000 4280 4000 0 0
								11000 4430 3800 0 0
								11000 4430 3500 0 0
								11000 4475 3300 0 0
								11000 4475 3000 0 0
								11000 4475 2500 0 0
								11000 4475 2000 0 0
								11000 4475 1500 0 0
								11000 4485 1000 1 0>;
				strategy_temp_warm =		<11000 4120 1600 0 0
								11000 4120 1500 0 0
								11000 4130 1000 1 0>;
			};
			strategy_soc_range_mid {
				strategy_temp_little_cold =	<11000 4140 1300 0 0
								11000 4150 1000 1 0>;
				strategy_temp_cool =		<11000 4150 1500 0 0
								11000 4490 1300 0 0
								11000 4490 1000 1 0>;
				strategy_temp_little_cool =	<11000 4330 2000 0 0
								11000 4330 1500 0 0
								11000 4490 1300 0 0
								11000 4500 1000 1 0>;
				strategy_temp_little_cool_high =	<11000 4490 2000 0 0
								11000 4490 1500 0 0
								11000 4500 1000 1 0>;
				strategy_temp_normal_low =	<11000 4490 2000 0 0
								11000 4490 1500 0 0
								11000 4500 1000 1 0>;
				strategy_temp_normal_high =	<11000 4475 2500 0 0
								11000 4475 2000 0 0
								11000 4475 1500 0 0
								11000 4485 1000 1 0>;
				strategy_temp_warm =		<11000 4120 1600 0 0
								11000 4120 1500 0 0
								11000 4130 1000 1 0>;
			};
			strategy_soc_range_mid_high {
				strategy_temp_little_cold =	<11000 4150 1000 1 0>;
				strategy_temp_cool =		<11000 4490 1000 1 0>;
				strategy_temp_little_cool =	<11000 4330 1500 0 0
								11000 4490 1300 0 0
								11000 4500 1000 1 0>;
				strategy_temp_little_cool_high =	<11000 4490 1500 0 0
								11000 4500 1000 1 0>;
				strategy_temp_normal_low =	<11000 4490 1500 0 0
								11000 4500 1000 1 0>;
				strategy_temp_normal_high =	<11000 4475 1500 0 0
								11000 4485 1000 1 0>;
				strategy_temp_warm =		<11000 4120 1600 0 0
								11000 4120 1500 0 0
								11000 4130 1000 1 0>;
			};
			strategy_soc_range_high {
				strategy_temp_little_cold =	<11000 4150 1000 1 0>;
				strategy_temp_cool =		<11000 4490 1000 1 0>;
				strategy_temp_little_cool =	<11000 4500 1000 1 0>;
				strategy_temp_little_cool_high =	<11000 4500 1000 1 0>;
				strategy_temp_normal_low =	<11000 4500 1000 1 0>;
				strategy_temp_normal_high =	<11000 4485 1000 1 0>;
				strategy_temp_warm =		<11000 4130 1000 1 0>;
			};
		};

		oplus,impedance_node {
			ufcs_input_impedance: ufcs_input_impedance {
				node_name = "ufcs_input";
				default_impedance_mohm = <0>;
				default_curr_ma = <4000>;
				current_drop_table = <
					250 4000
					340 3000
					380 2000
					480 0
				>;
			};
		};
	};

	oplus_virtual_dpdm_switch: oplus,virtual_dpdm_switch {
		compatible = "oplus,virtual_dpdm_switch";

		oplus,ic_type = <OPLUS_CHG_IC_MISC>;
		oplus,ic_index = <0>;

		oplus,use_audio_switch;
	};
};

&soc {
	oplus_ufcs_impedance_check: oplus,ufcs_impedance_check {
		compatible = "oplus,impedance_check";

		oplus,impedance_unit {
			oplus_ufcs_impedance_unit: oplus,ufcs_impedance_unit {
				uint_name = "ufcs";
				default_curr_ma = <4000>;
				impedance_node = <&ufcs_input_impedance>;
			};
		};
	};
};

&pio {
	i2c1_i2c_state: i2c1_sda_i2c_state {
		pins_cmd_dat {
			pinmux = <PINMUX_GPIO100__FUNC_SCL1>,
			<PINMUX_GPIO101__FUNC_SDA1>;
			bias-pull-up;
		};
	};
	i2c1_output_low_state: i2c1_sda_output_low_state {
		pins_cmd_dat {
			pinmux = <PINMUX_GPIO100__FUNC_GPIO100>,
			<PINMUX_GPIO101__FUNC_GPIO101>;
			output-low;
		};
	};
};

&i2c1 {
	status = "okay";
	clock-frequency = <400000>;
	oplus_sc8547a: oplus,sc8547a@6F{
		status = "okay";
		compatible = "oplus,sc8547a";
		reg = <0x6F>;

		oplus,use_vooc_phy;
		oplus,use_ufcs_phy;
		oplus,irq_gpio = <&pio 83 0x00>;

		pinctrl-names = "charging_inter_active", "charging_inter_sleep", "i2c-state", "output-low-state";
		pinctrl-0 = <&charging_inter_active>;
		pinctrl-1 = <&charging_inter_sleep>;
		pinctrl-2 = <&i2c1_i2c_state>;
		pinctrl-3 = <&i2c1_output_low_state>;

		oplus,ic_type = <OPLUS_CHG_IC_VPHY>;
		oplus,ic_index = <0>;
		oplus,vooc-version = <VOOC_VERSION_5_0>;

		ocp_reg = <0xd>;
		ovp_reg = <0x36>;/* vbat ovp 4.85v */
		oplus_spec,voocphy_dual_cp_support;
		oplus_spec,slave_cp_enable_thr = <1400>;		//2000-100mA
		oplus_spec,slave_cp_disable_thr_high = <1100>;	//1500+100mA
		oplus_spec,voocphy_current_default = <73>;

		oplus_spec,external_gauge_support;

		oplus_spec,svooc_cool_down_current_limit = <146 20 20 24 30 34 40 44 50 54 60 64 70 74>;
		oplus_spec,vooc_cool_down_current_limit = <73 20 20 24 30 34 40 44 50 54 60 64 70 74>;

		oplus_spec,vooc_little_cold_full_voltage = <4570>;
		oplus_spec,vooc_cool_full_voltage = <4570>;
		oplus_spec,vooc_little_cool_full_voltage = <4570>;
		oplus_spec,vooc_little_cool_high_full_voltage = <4570>;
		oplus_spec,vooc_warm_full_voltage = <4130>;
		oplus_spec,vooc_1time_full_voltage = <4580>;
		oplus_spec,vooc_ntime_full_voltage = <4570>;
		oplus_spec,full_voltage = < /* vol_1time vol_ntime */
					4580 4570 /* 0 ~ 5 */
					4580 4570 /* 5 ~ 12 */
					4580 4570 /* 12 ~ 16 */
					4580 4570 /* 16 ~ 20 */
					4580 4570 /* 20 ~ 35 */
					4580 4570 /* 35 ~ 44 */
					4140 4130 /* 44 ~ 51 */
					>;

		oplus_spec,impedance_calculation_newmethod;
		oplus_spec,svooc_circuit_r_l = <0xa>;
		oplus_spec,svooc_circuit_r_h = <0x1>;
		oplus_spec,fastchg_timeout_time_init = <176140>;
		oplus_spec,vooc_multistep_initial_batt_temp = <1000>;
		oplus_spec,vooc_little_cool_temp = <160>;
		oplus_spec,vooc_little_cool_high_temp = <210>;
		oplus_spec,vooc_cool_temp = <120>;
		oplus_spec,vooc_little_cold_temp = <50>;
		oplus_spec,vooc_normal_low_temp = <350>;
		oplus_spec,vooc_strategy_normal_current = <146>;
		oplus_spec,vooc_normal_to_little_cool_current = <100>;
		oplus_spec,vooc_over_high_temp = <510>;
		oplus_spec,vooc_low_temp = <0>;
		oplus_spec,vooc_high_temp = <500>;
		oplus_spec,vooc_low_soc = <0>;
		oplus_spec,vooc_high_soc = <95>;
		oplus_spec,vooc_normal_high_temp = <440>;
		oplus_spec,vooc_warm_vol_thr = <4000>;
		oplus_spec,vooc_warm_soc_thr = <55>;

		oplus_spec,vooc_strategy1_batt_high_temp0 = <390>;
		oplus_spec,vooc_strategy1_batt_high_temp1 = <410>;
		oplus_spec,vooc_strategy1_batt_high_temp2 = <430>;
		oplus_spec,vooc_strategy1_batt_low_temp2 = <410>;
		oplus_spec,vooc_strategy1_batt_low_temp1 = <390>;
		oplus_spec,vooc_strategy1_batt_low_temp0 = <380>;

		oplus_spec,vooc_strategy1_high_current0 = <80>;
		oplus_spec,vooc_strategy1_high_current1 = <60>;
		oplus_spec,vooc_strategy1_high_current2 = <40>;
		oplus_spec,vooc_strategy1_low_current2 = <60>;
		oplus_spec,vooc_strategy1_low_current1 = <80>;
		oplus_spec,vooc_strategy1_low_current0 = <146>;

		oplus_spec,voocphy_freq_mincore = <925000>;
		oplus_spec,voocphy_freq_midcore = <1718000>;
		oplus_spec,voocphy_freq_maxcore = <1718000>;
		oplus_spec,voocphy_current_change_timeout = <100>;
		oplus_spec,copycat_vooc_support;
		oplus_spec,copycat_vooc_accuracy_value = <105>;
		oplus_spec,soc_range = <0 20 35 55 75 85 95>;
		oplus_spec,voocphy_ibat_over_current = <16000>;
		oplus_spec,voocphy_svooc_cp_max_ibus = <5000>;
		oplus_spec,voocphy_vooc_cp_max_ibus = <5000>;
		oplus_spec,voocphy_cp_max_ibus = <5000>;
		svooc_batt_sys_curve = <0 1 0 1 0 0 0	// 4000mA
					1 1 1 1 0 0 0	// 4604mV
					0 0 1 1 0 1 0	// 2600mA
					1 1 1 1 0 0 0	// 4604mV
					0 0 0 1 0 1 1	// 1100mA
					1 1 1 1 0 0 0>;	// 4604mV

		vooc_batt_sys_curve =  <0 1 0 1 0 0 0	// 4000mA
					1 1 1 1 0 0 0	// 4604mV
					0 0 1 1 0 1 0	// 2600mA
					1 1 1 1 0 0 0	// 4604mV
					0 0 0 1 0 1 1	// 1100mA
					1 1 1 1 0 0 0>;	// 4604mV

		svooc_lcf_strategy {
			oplus,temp_type = <OPLUS_STRATEGY_USE_SHELL_TEMP>;
			oplus,temp_range = <0 50 120 160 210 380 440>;

			strategy_temp_range_curves {
				strategy_temp_range_t0 =	<760 4570 0
								 735 4560 0
								 710 4550 0
								 685 4540 0
								 660 4530 1>;
				strategy_temp_range_t1 =	<800 4570 0
								 765 4565 0
								 730 4550 0
								 695 4540 0
								 660 4530 1>;
				strategy_temp_range_t2 =	<1150 4570 0
								 1100 4565 0
								 1000 4550 0
								 900 4540 0
								 750 4530 1>;
				strategy_temp_range_t3 =	<1850 4570 0
								 1800 4565 0
								 1700 4550 0
								 1600 4540 0
								 1450 4530 1>;
				strategy_temp_range_t4 =	<1850 4570 0
								 1800 4565 0
								 1700 4550 0
								 1600 4540 0
								 1450 4530 1>;
				strategy_temp_range_t5 =	<2350 4570 0
								 2300 4565 0
								 2200 4550 0
								 2100 4540 0
								 1950 4530 1>;
			};
		};

		svooc_charge_strategy {
			strategy_soc_0_to_50 { /* 0 ~ 20 */
				strategy_temp_little_cold =	<4150 39 0 0 0
								4150 35 0 0 0
								4510 32 0 0 0
								4510 30 0 0 0
								4510 25 0 0 0
								4560 23 0 0 0
								4560 20 0 0 0
								4560 15 0 0 0
								4570 10 1 0 0>;
				strategy_temp_cool =		<4150 49 0 0 0
								4150 45 0 0 0
								4150 40 0 0 0
								4510 39 0 0 0
								4510 35 0 0 0
								4510 30 0 0 0
								4560 25 0 0 0
								4560 20 0 0 0
								4560 15 0 0 0
								4570 10 1 0 0>;
				strategy_temp_little_cool =	<4150 73 0 0 0
								4150 61 0 0 0
								4510 59 0 0 0
								4510 50 0 0 0
								4560 49 0 0 0
								4560 40 0 0 0
								4560 35 0 0 0
								4560 30 0 0 0
								4560 25 0 0 0
								4560 20 0 0 0
								4560 15 0 0 0
								4570 10 1 0 0>;
				strategy_temp_little_cool_high =	<4280 73 0 0 0
								4510 62 0 0 0
								4510 50 0 0 0
								4560 46 0 0 0
								4560 40 0 0 0
								4560 35 0 0 0
								4560 30 0 0 0
								4560 25 0 0 0
								4560 20 0 0 0
								4560 15 0 0 0
								4570 10 1 0 0>;
				strategy_temp_normal_low =	<4280 73 0 0 0
								4510 62 0 0 0
								4510 50 0 0 0
								4560 46 0 0 0
								4560 40 0 0 0
								4560 35 0 0 0
								4560 30 0 0 0
								4560 25 0 0 0
								4560 20 0 0 0
								4560 15 0 0 0
								4570 10 1 0 0>;
				strategy_temp_normal_high =	<4280 73 0 0 0
								4510 62 0 0 0
								4510 50 0 0 0
								4560 46 0 0 0
								4560 40 0 0 0
								4560 35 0 0 0
								4560 30 0 0 0
								4560 25 0 0 0
								4560 20 0 0 0
								4560 15 0 0 0
								4570 12 1 0 0>;
				strategy_temp_warm =		<4120 18 0 0 0
								4120 15 0 0 0
								4130 10 1 0 0>;
			};

			strategy_soc_0_to_50_mid { /* 21 ~ 35 */
				strategy_temp_little_cold =	<4150 39 0 0 0
								4150 35 0 0 0
								4510 32 0 0 0
								4510 30 0 0 0
								4510 25 0 0 0
								4560 23 0 0 0
								4560 20 0 0 0
								4560 15 0 0 0
								4570 10 1 0 0>;
				strategy_temp_cool =		<4150 49 0 0 0
								4150 45 0 0 0
								4150 40 0 0 0
								4510 39 0 0 0
								4510 35 0 0 0
								4510 30 0 0 0
								4560 25 0 0 0
								4560 20 0 0 0
								4560 15 0 0 0
								4570 10 1 0 0>;
				strategy_temp_little_cool =	<4150 73 0 0 0
								4150 61 0 0 0
								4510 59 0 0 0
								4510 50 0 0 0
								4560 49 0 0 0
								4560 40 0 0 0
								4560 35 0 0 0
								4560 30 0 0 0
								4560 25 0 0 0
								4560 20 0 0 0
								4560 15 0 0 0
								4570 10 1 0 0>;
				strategy_temp_little_cool_high =	<4280 73 0 0 0
								4510 62 0 0 0
								4510 50 0 0 0
								4560 46 0 0 0
								4560 40 0 0 0
								4560 35 0 0 0
								4560 30 0 0 0
								4560 25 0 0 0
								4560 20 0 0 0
								4560 15 0 0 0
								4570 10 1 0 0>;
				strategy_temp_normal_low =	<4280 73 0 0 0
								4510 62 0 0 0
								4510 50 0 0 0
								4560 46 0 0 0
								4560 40 0 0 0
								4560 35 0 0 0
								4560 30 0 0 0
								4560 25 0 0 0
								4560 20 0 0 0
								4560 15 0 0 0
								4570 10 1 0 0>;
				strategy_temp_normal_high =	<4280 73 0 0 0
								4510 62 0 0 0
								4510 50 0 0 0
								4560 46 0 0 0
								4560 40 0 0 0
								4560 35 0 0 0
								4560 30 0 0 0
								4560 25 0 0 0
								4560 20 0 0 0
								4560 15 0 0 0
								4570 12 1 0 0>;
				strategy_temp_warm =		<4120 18 0 0 0
								4120 15 0 0 0
								4130 10 1 0 0>;
			};

			strategy_soc_0_to_50_high { /* 36 ~ 55 */
				strategy_temp_little_cold =	<4560 20 0 0 0
								4560 15 0 0 0
								4570 10 1 0 0>;
				strategy_temp_cool =		<4560 25 0 0 0
								4560 20 0 0 0
								4560 15 0 0 0
								4570 10 1 0 0>;
				strategy_temp_little_cool =	<4560 40 0 0 0
								4560 35 0 0 0
								4560 30 0 0 0
								4560 25 0 0 0
								4560 20 0 0 0
								4560 15 0 0 0
								4570 10 1 0 0>;
				strategy_temp_little_cool_high =	<4560 40 0 0 0
								4560 35 0 0 0
								4560 30 0 0 0
								4560 25 0 0 0
								4560 20 0 0 0
								4560 15 0 0 0
								4570 10 1 0 0>;
				strategy_temp_normal_low =	<4280 73 0 0 0
								4510 62 0 0 0
								4510 50 0 0 0
								4560 46 0 0 0
								4560 40 0 0 0
								4560 35 0 0 0
								4560 30 0 0 0
								4560 25 0 0 0
								4560 20 0 0 0
								4560 15 0 0 0
								4570 10 1 0 0>;
				strategy_temp_normal_high =	<4280 73 0 0 0
								4510 62 0 0 0
								4510 50 0 0 0
								4560 46 0 0 0
								4560 40 0 0 0
								4560 35 0 0 0
								4560 30 0 0 0
								4560 25 0 0 0
								4560 20 0 0 0
								4560 15 0 0 0
								4570 12 1 0 0>;
				strategy_temp_warm =		<4120 18 0 0 0
								4120 15 0 0 0
								4130 10 1 0 0>;
			};

			strategy_soc_50_to_75 { /* 56 ~ 75 */
				strategy_temp_little_cold =	<4560 15 0 0 0
								4570 10 1 0 0>;
				strategy_temp_cool =		<4560 15 0 0 0
								4570 10 1 0 0>;
				strategy_temp_little_cool =	<4560 20 0 0 0
								4560 15 0 0 0
								4570 10 1 0 0>;
				strategy_temp_little_cool_high =	<4560 20 0 0 0
								4560 15 0 0 0
								4570 10 1 0 0>;
				strategy_temp_normal_low =	<4560 25 0 0 0
								4560 20 0 0 0
								4560 15 0 0 0
								4570 10 1 0 0>;
				strategy_temp_normal_high =	<4560 30 0 0 0
								4560 25 0 0 0
								4560 20 0 0 0
								4560 15 0 0 0
								4570 12 1 0 0>;
				strategy_temp_warm =		<4120 18 0 0 0
								4120 15 0 0 0
								4130 10 1 0 0>;
			};

			strategy_soc_75_to_85 { /* 76 ~ 85 */
				strategy_temp_little_cold =	<4570 10 0 0 0>;
				strategy_temp_cool =		<4570 10 1 0 0>;
				strategy_temp_little_cool =	<4560 15 0 0 0
								4570 10 1 0 0>;
				strategy_temp_little_cool_high =	<4560 15 0 0 0
								4570 10 1 0 0>;
				strategy_temp_normal_low =	<4540 15 0 0 0
								4550 10 1 0 0>;
				strategy_temp_normal_high =	<4560 20 0 0 0
								4560 15 0 0 0
								4570 12 1 0 0>;
				strategy_temp_warm =		<4120 18 0 0 0
								4120 15 0 0 0
								4130 10 1 0 0>;
			};

			strategy_soc_85_to_90 { /* 86 ~ 95 */
				strategy_temp_little_cold =	<4570 10 1 0 0>;
				strategy_temp_cool =		<4570 10 1 0 0>;
				strategy_temp_little_cool =	<4570 10 1 0 0>;
				strategy_temp_little_cool_high = <4570 10 1 0 0>;
				strategy_temp_normal_low =	<4570 10 1 0 0>;
				strategy_temp_normal_high =	<4570 12 1 0 0>;
				strategy_temp_warm =		<4130 10 1 0 0>;
			};
		};

		vooc_charge_strategy {
			strategy_soc_0_to_50 {
				strategy_temp_little_cold =	<4510 60 0 0 0
								4510 50 0 0 0
								4560 46 0 0 0
								4560 40 0 0 0
								4560 30 0 0 0
								4570 20 1 0 0>;
				strategy_temp_cool =		<4510 60 0 0 0
								4560 50 0 0 0
								4560 40 0 0 0
								4560 30 0 0 0
								4570 20 1 0 0>;
				strategy_temp_little_cool =	<4560 60 0 0 0
								4560 50 0 0 0
								4560 40 0 0 0
								4560 30 0 0 0
								4570 20 1 0 0>;
				strategy_temp_little_cool_high =	<4560 60 0 0 0
								4560 50 0 0 0
								4560 40 0 0 0
								4560 30 0 0 0
								4570 20 1 0 0>;
				strategy_temp_normal_low =	<4560 60 0 0 0
								4560 50 0 0 0
								4560 40 0 0 0
								4560 30 0 0 0
								4570 20 1 0 0>;
				strategy_temp_normal_high =	<4560 60 0 0 0
								4560 50 0 0 0
								4560 40 0 0 0
								4560 30 0 0 0
								4570 24 1 0 0>;
				strategy_temp_warm =		<4120 36 0 0 0
								4120 30 0 0 0
								4130 20 1 0 0>;
			};

			strategy_soc_0_to_50_mid {
				strategy_temp_little_cold =	<4510 60 0 0 0
								4510 50 0 0 0
								4560 46 0 0 0
								4560 40 0 0 0
								4560 30 0 0 0
								4570 20 1 0 0>;
				strategy_temp_cool =		<4510 60 0 0 0
								4560 50 0 0 0
								4560 40 0 0 0
								4560 30 0 0 0
								4570 20 1 0 0>;
				strategy_temp_little_cool =	<4560 60 0 0 0
								4560 50 0 0 0
								4560 40 0 0 0
								4560 30 0 0 0
								4570 20 1 0 0>;
				strategy_temp_little_cool_high =	<4560 60 0 0 0
								4560 50 0 0 0
								4560 40 0 0 0
								4560 30 0 0 0
								4570 20 1 0 0>;
				strategy_temp_normal_low =	<4560 60 0 0 0
								4560 50 0 0 0
								4560 40 0 0 0
								4560 30 0 0 0
								4570 20 1 0 0>;
				strategy_temp_normal_high =	<4560 60 0 0 0
								4560 50 0 0 0
								4560 40 0 0 0
								4560 30 0 0 0
								4570 24 1 0 0>;
				strategy_temp_warm =		<4120 36 0 0 0
								4120 30 0 0 0
								4130 20 1 0 0>;
			};

			strategy_soc_0_to_50_high {
				strategy_temp_little_cold =	<4560 40 0 0 0
								4560 30 0 0 0
								4570 20 1 0 0>;
				strategy_temp_cool =		<4560 50 0 0 0
								4560 40 0 0 0
								4560 30 0 0 0
								4570 20 1 0 0>;
				strategy_temp_little_cool =	<4560 60 0 0 0
								4560 50 0 0 0
								4560 40 0 0 0
								4560 30 0 0 0
								4570 20 1 0 0>;
				strategy_temp_little_cool_high =	<4560 60 0 0 0
								4560 50 0 0 0
								4560 40 0 0 0
								4560 30 0 0 0
								4570 20 1 0 0>;
				strategy_temp_normal_low =	<4560 60 0 0 0
								4560 50 0 0 0
								4560 40 0 0 0
								4560 30 0 0 0
								4570 20 1 0 0>;
				strategy_temp_normal_high =	<4560 60 0 0 0
								4560 50 0 0 0
								4560 40 0 0 0
								4560 30 0 0 0
								4570 24 1 0 0>;
				strategy_temp_warm =		<4120 36 0 0 0
								4120 30 0 0 0
								4130 20 1 0 0>;
			};

			strategy_soc_50_to_75 {
				strategy_temp_little_cold =	<4560 30 0 0 0
								4570 20 1 0 0>;
				strategy_temp_cool =		<4560 30 0 0 0
								4570 20 1 0 0>;
				strategy_temp_little_cool =	<4560 40 0 0 0
								4560 30 0 0 0
								4570 20 1 0 0>;
				strategy_temp_little_cool_high =	<4560 40 0 0 0
								4560 30 0 0 0
								4570 20 1 0 0>;
				strategy_temp_normal_low =	<4560 50 0 0 0
								4560 40 0 0 0
								4560 30 0 0 0
								4570 20 1 0 0>;
				strategy_temp_normal_high =	<4560 60 0 0 0
								4560 50 0 0 0
								4560 40 0 0 0
								4560 30 0 0 0
								4570 24 1 0 0>;
				strategy_temp_warm =		<4120 36 0 0 0
								4120 30 0 0 0
								4130 20 1 0 0>;
			};

			strategy_soc_75_to_85 {
				strategy_temp_little_cold =	<4570 20 1 0 0>;
				strategy_temp_cool =		<4570 20 1 0 0>;
				strategy_temp_little_cool =	<4560 30 0 0 0
								4570 20 1 0 0>;
				strategy_temp_little_cool_high =	<4560 30 0 0 0
								4570 20 1 0 0>;
				strategy_temp_normal_low =	<4560 30 0 0 0
								4570 20 1 0 0>;
				strategy_temp_normal_high =	<4560 40 0 0 0
								4560 30 0 0 0
								4570 24 1 0 0>;
				strategy_temp_warm =		<4120 36 0 0 0
								4120 30 0 0 0
								4130 20 1 0 0>;
			};

			strategy_soc_85_to_90 {
				strategy_temp_little_cold =	<4570 20 1 0 0>;
				strategy_temp_cool =		<4570 20 1 0 0>;
				strategy_temp_little_cool =	<4570 20 1 0 0>;
				strategy_temp_little_cool_high =	<4570 20 1 0 0>;
				strategy_temp_normal_low =	<4570 20 1 0 0>;
				strategy_temp_normal_high =	<4570 24 1 0 0>;
				strategy_temp_warm =		<4130 20 1 0 0>;
			};
		};
		oplus_sc8547_cp: oplus,sc8547_cp {
			oplus,ic_type = <OPLUS_CHG_IC_CP>;
			oplus,ic_index = <0>;
			oplus,ic_func_group = <&sc8547_cp_groups>;
		};
	};
};

&i2c13 {
	status = "okay";
	clock-frequency = <400000>;
	oplus_sc8547_slave: sc8547-charger-slave@6F{
		status = "okay";
		compatible = "slave_vphy_sc8547";
		reg = <0x6F>;

		ocp_reg = <0xd>;
		ovp_reg = <0x36>;/* vbat ovp 4.85v */
		oplus_sc8547_slave_cp: oplus,sc8547_slave_cp {
			oplus,ic_type = <OPLUS_CHG_IC_CP>;
			oplus,ic_index = <1>;
			oplus,ic_func_group = <&sc8547_cp_groups>;
		};
	};
};
&charger {
	oplus_ap_pps: oplus,ap_pps {
		oplus,ic_type = <OPLUS_CHG_IC_PPS>;
		oplus,ic_index = <0>;
	};
};

&soc {
	oplus_virtual_pps: oplus,virtual_pps {
		compatible = "oplus,virtual_pps";

		oplus,ic_type = <OPLUS_CHG_IC_VIRTUAL_PPS>;
		oplus,ic_index = <0>;
		oplus,pps_ic = <&oplus_ap_pps>;
	};
	oplus_pps_charge: oplus,pps_charge {
		compatible = "oplus,pps_charge";
		oplus,pps_ic = <&oplus_virtual_pps>;
		oplus,cp_ic = <&oplus_virtual_cp>;
		oplus,dpdm_switch_ic = <&oplus_virtual_dpdm_switch>;

		// oplus,impedance_unit = <&oplus_pps_impedance_unit>;

		oplus,target_vbus_mv = <11000>;
		oplus,curr_max_ma = <5000>;

		oplus,pps_warm_allow_vol = <4000>;
		oplus,pps_warm_allow_soc = <55>;
		oplus,pps_strategy_normal_current = <5000>;
		oplus,pps_over_high_or_low_current = <5000>;
		oplus,pps_timeout_third = <17614>;
		oplus,pps_timeout_oplus = <17614>;
		oplus,pps_ibat_over_third = <12000>;
		oplus,pps_ibat_over_oplus = <12000>;
		oplus,pps_full_cool_sw_vbat = <4470>;
		oplus,pps_full_normal_sw_vbat = <4470>;
		oplus,pps_full_normal_hw_vbat = <4480>;
		oplus,pps_full_ffc_vbat = <4520>;
		oplus,pps_full_warm_vbat = <4130>;
		oplus,pps_full_cool_sw_vbat_third = <4470>;
		oplus,pps_full_normal_sw_vbat_third= <4470>;
		oplus,pps_full_normal_hw_vbat_third = <4480>;
		oplus,pps_current_change_timeout = <100>;
		oplus,pps_r_default = <270 45 10 45 20 20 20>;
		oplus,pps_rmos_mohm = <5>;
		oplus,pps_little_cool_high_temp = <210>;
		oplus,curve_strategy_name = "pps_ufcs_curve_v2";
		oplus,pps_r_limit = <150 100 80 70 30>;
		oplus,pps_strategy_batt_high_temp = <385 420 425 375 415 420>;
		oplus,pps_strategy_high_current = <5000 2500 2000 5000 5000 2500>;
		oplus,pps_charge_strategy_soc = <0 20 35 55 75 85 95>;
		oplus,pps_charge_strategy_temp = <0 50 120 160 350 440 510>;
		oplus,pps_low_curr_full_strategy_temp = <0 200 350 440>;

		pps_oplus_lcf_strategy {
			oplus,temp_type = <OPLUS_STRATEGY_USE_SHELL_TEMP>;
			oplus,temp_range = <0 50 120 160 210 380 430>;

			strategy_temp_range_curves {
				strategy_temp_range_t0 =	<420 4570 0
								 395 4565 0
								 370 4550 0
								 345 4540 0
								 320 4530 1>;
				strategy_temp_range_t1 =	<550 4570 0
								 515 4565 0
								 480 4550 0
								 445 4540 0
								 410 4530 1>;
				strategy_temp_range_t2 =	<700 4570 0
								 655 4565 0
								 610 4550 0
								 565 4540 0
								 520 4530 1>;
				strategy_temp_range_t3 =	<850 4570 0
								 800 4565 0
								 700 4550 0
								 600 4540 0
								 450 4530 1>;
				strategy_temp_range_t4 =	<1750 4575 0
								 1700 4570 0
								 1600 4555 0
								 1500 4545 0
								 1350 4535 1>;
				strategy_temp_range_t5 =	<2000 4570 0
								 1950 4565 0
								 1850 4550 0
								 1750 4540 0
								 1600 4530 1>;
			};
		};

		pps_third_lcf_strategy {
			oplus,temp_type = <OPLUS_STRATEGY_USE_SHELL_TEMP>;
			oplus,temp_range = <0 50 120 160 210 380 440>;

			strategy_temp_range_curves {
				strategy_temp_range_t0 =	<850 4550 0
								 800 4540 0
								 750 4530 0
								 700 4520 0
								 650 4510 1>;
				strategy_temp_range_t1 =	<750 4550 0
								 700 4540 0
								 650 4530 0
								 550 4520 0
								 450 4510 1>;
				strategy_temp_range_t2 =	<850 4550 0
								 805 4540 0
								 760 4530 0
								 715 4520 0
								 670 4510 1>;
				strategy_temp_range_t3 =	<900 4550 0
								 850 4540 0
								 750 4530 0
								 650 4520 0
								 500 4510 1>;
				strategy_temp_range_t4 =	<1250 4550 0
								 1200 4540 0
								 1100 4530 0
								 1000 4520 0
								 850 4510 1>;
				strategy_temp_range_t5 =	<1900 4550 0
								 1850 4540 0
								 1750 4530 0
								 1650 4520 0
								 1500 4510 1>;
			};
		};

		pps_charge_third_strategy {
			oplus,temp_type = <OPLUS_STRATEGY_USE_SHELL_TEMP>;
			oplus,soc_range = <0 20 35 55 75 85 95>;
			oplus,temp_range = <0 50 120 160 210 350 440 510>;

			strategy_soc_range_min {
				strategy_temp_little_cold =	<11000 4150 3950 0 0
								11000 4150 3500 0 0
								11000 4490 3250 0 0
								11000 4490 3000 0 0
								11000 4490 2550 0 0
								11000 4490 2500 0 0
								11000 4490 2000 0 0
								11000 4490 1500 0 0
								11000 4500 1000 1 0>;
				strategy_temp_cool =		<11000 4150 4900 0 0
								11000 4150 4500 0 0
								11000 4150 4000 0 0
								11000 4490 3950 0 0
								11000 4490 3500 0 0
								11000 4490 3000 0 0
								11000 4490 2550 0 0
								11000 4490 2500 0 0
								11000 4490 2000 0 0
								11000 4490 1500 0 0
								11000 4500 1000 1 0>;
				strategy_temp_little_cool =	<11000 4490 5000 0 0
								11000 4490 4900 0 0
								11000 4490 4000 0 0
								11000 4490 3500 0 0
								11000 4490 3000 0 0
								11000 4490 2500 0 0
								11000 4490 2000 0 0
								11000 4490 1500 0 0
								11000 4500 1000 1 0>;
				strategy_temp_little_cool_high =	<11000 4490 5000 0 0
								11000 4490 4600 0 0
								11000 4490 4000 0 0
								11000 4490 3500 0 0
								11000 4490 3000 0 0
								11000 4490 2500 0 0
								11000 4490 2000 0 0
								11000 4490 1500 0 0
								11000 4500 1000 1 0>;
				strategy_temp_normal_low =	<11000 4490 5000 0 0
								11000 4490 4600 0 0
								11000 4490 4000 0 0
								11000 4490 3500 0 0
								11000 4490 3000 0 0
								11000 4490 2500 0 0
								11000 4490 2000 0 0
								11000 4490 1500 0 0
								11000 4500 1000 1 0>;
				strategy_temp_normal_high =	<11000 4465 5000 0 0
								11000 4465 4600 0 0
								11000 4465 4000 0 0
								11000 4465 3500 0 0
								11000 4465 3000 0 0
								11000 4465 2500 0 0
								11000 4465 2000 0 0
								11000 4465 1500 0 0
								11000 4475 1000 1 0>;
				strategy_temp_warm =		<11000 4120 1850 0 0
								11000 4120 1500 0 0
								11000 4130 1000 1 0>;
			};
			strategy_soc_range_low {
				strategy_temp_little_cold =	<11000 4150 3950 0 0
								11000 4150 3500 0 0
								11000 4490 3250 0 0
								11000 4490 3000 0 0
								11000 4490 2550 0 0
								11000 4490 2500 0 0
								11000 4490 2000 0 0
								11000 4490 1500 0 0
								11000 4500 1000 1 0>;
				strategy_temp_cool =		<11000 4150 4900 0 0
								11000 4150 4500 0 0
								11000 4150 4000 0 0
								11000 4490 3950 0 0
								11000 4490 3500 0 0
								11000 4490 3000 0 0
								11000 4490 2550 0 0
								11000 4490 2500 0 0
								11000 4490 2000 0 0
								11000 4490 1500 0 0
								11000 4500 1000 1 0>;
				strategy_temp_little_cool =	<11000 4490 5000 0 0
								11000 4490 4900 0 0
								11000 4490 4000 0 0
								11000 4490 3500 0 0
								11000 4490 3000 0 0
								11000 4490 2500 0 0
								11000 4490 2000 0 0
								11000 4490 1500 0 0
								11000 4500 1000 1 0>;
				strategy_temp_little_cool_high =	<11000 4490 5000 0 0
								11000 4490 4600 0 0
								11000 4490 4000 0 0
								11000 4490 3500 0 0
								11000 4490 3000 0 0
								11000 4490 2500 0 0
								11000 4490 2000 0 0
								11000 4490 1500 0 0
								11000 4500 1000 1 0>;
				strategy_temp_normal_low =	<11000 4490 5000 0 0
								11000 4490 4600 0 0
								11000 4490 4000 0 0
								11000 4490 3500 0 0
								11000 4490 3000 0 0
								11000 4490 2500 0 0
								11000 4490 2000 0 0
								11000 4490 1500 0 0
								11000 4500 1000 1 0>;
				strategy_temp_normal_high =	<11000 4465 5000 0 0
								11000 4465 4600 0 0
								11000 4465 4000 0 0
								11000 4465 3500 0 0
								11000 4465 3000 0 0
								11000 4465 2500 0 0
								11000 4465 2000 0 0
								11000 4465 1500 0 0
								11000 4475 1000 1 0>;
				strategy_temp_warm =		<11000 4120 1850 0 0
								11000 4120 1500 0 0
								11000 4130 1000 1 0>;
			};
			strategy_soc_range_mid_low {
				strategy_temp_little_cold =	<11000 4490 2000 0 0
								11000 4490 1500 0 0
								11000 4500 1000 1 0>;
				strategy_temp_cool =		<11000 4490 2500 0 0
								11000 4490 2000 0 0
								11000 4490 1500 0 0
								11000 4500 1000 1 0>;
				strategy_temp_little_cool =	<11000 4490 4000 0 0
								11000 4490 3500 0 0
								11000 4490 3000 0 0
								11000 4490 2500 0 0
								11000 4490 2000 0 0
								11000 4490 1500 0 0
								11000 4500 1000 1 0>;
				strategy_temp_little_cool_high =	<11000 4490 4000 0 0
								11000 4490 3500 0 0
								11000 4490 3000 0 0
								11000 4490 2500 0 0
								11000 4490 2000 0 0
								11000 4490 1500 0 0
								11000 4500 1000 1 0>;
				strategy_temp_normal_low =	<11000 4490 5000 0 0
								11000 4490 4600 0 0
								11000 4490 4000 0 0
								11000 4490 3500 0 0
								11000 4490 3000 0 0
								11000 4490 2500 0 0
								11000 4490 2000 0 0
								11000 4490 1500 0 0
								11000 4500 1000 1 0>;
				strategy_temp_normal_high =	<11000 4465 5000 0 0
								11000 4465 4600 0 0
								11000 4465 4000 0 0
								11000 4465 3500 0 0
								11000 4465 3000 0 0
								11000 4465 2500 0 0
								11000 4465 2000 0 0
								11000 4465 1500 0 0
								11000 4475 1000 1 0>;
				strategy_temp_warm =		<11000 4120 1850 0 0
								11000 4120 1500 0 0
								11000 4130 1000 1 0>;
			};
			strategy_soc_range_mid {
				strategy_temp_little_cold =	<11000 4490 1500 0 0
								11000 4500 1000 1 0>;
				strategy_temp_cool =		<11000 4490 1500 0 0
								11000 4500 1000 1 0>;
				strategy_temp_little_cool =	<11000 4490 2000 0 0
								11000 4490 1500 0 0
								11000 4500 1000 1 0>;
				strategy_temp_little_cool_high =	<11000 4490 2000 0 0
								11000 4490 1500 0 0
								11000 4500 1000 1 0>;
				strategy_temp_normal_low =	<11000 4490 2000 0 0
								11000 4490 1500 0 0
								11000 4500 1000 1 0>;
				strategy_temp_normal_high =	<11000 4465 2500 0 0
								11000 4465 2000 0 0
								11000 4465 1500 0 0
								11000 4475 1000 1 0>;
				strategy_temp_warm =		<11000 4120 1850 0 0
								11000 4120 1500 0 0
								11000 4130 1000 1 0>;
			};
			strategy_soc_range_mid_high {
				strategy_temp_little_cold =	<11000 4500 1000 1 0>;
				strategy_temp_cool =		<11000 4500 1000 1 0>;
				strategy_temp_little_cool =	<11000 4490 1500 0 0
								11000 4500 1000 1 0>;
				strategy_temp_little_cool_high =	<11000 4490 1500 0 0
								11000 4500 1000 1 0>;
				strategy_temp_normal_low =	<11000 4490 1500 0 0
								11000 4500 1000 1 0>;
				strategy_temp_normal_high =	<11000 4465 1500 0 0
								11000 4475 1000 1 0>;
				strategy_temp_warm =		<11000 4120 1850 0 0
								11000 4120 1500 0 0
								11000 4130 1000 1 0>;
			};
			strategy_soc_range_high {
				strategy_temp_little_cold =	<11000 4500 1000 1 0>;
				strategy_temp_cool =		<11000 4500 1000 1 0>;
				strategy_temp_little_cool =	<11000 4500 1000 1 0>;
				strategy_temp_little_cool_high =	<11000 4500 1000 1 0>;
				strategy_temp_normal_low =	<11000 4500 1000 1 0>;
				strategy_temp_normal_high =	<11000 4475 1000 1 0>;
				strategy_temp_warm =		<11000 4130 1000 1 0>;
			};
		};

		pps_charge_oplus_strategy {
			oplus,temp_type = <OPLUS_STRATEGY_USE_SHELL_TEMP>;
			oplus,soc_range = <0 20 35 50 75 85 91>;
			oplus,temp_range = <0 50 120 160 200 350 440 510>;

			strategy_soc_range_min {
				strategy_temp_little_cold =	<11000 4150 1200 0 0
								11000 4150 1000 0 0
								11000 4570 700 1 0>;
				strategy_temp_cool =		<11000 4150 2100 0 0
								 11000 4150 2000 0 0
								11000 4150 1500 0 0
								11000 4510 1200 0 0
								11000 4510 1000 0 0
								11000 4570 700 1 0>;
				strategy_temp_little_cool =	<11000 4150 2700 0 0
								11000 4150 2500 0 0
								11000 4330 2100 0 0
								11000 4330 2000 0 0
								11000 4330 1500 0 0
								11000 4560 1200 0 0
								11000 4560 1000 0 0
								11000 4570 700 1 0>;
				strategy_temp_little_cool_high =	<11000 4150 2700 0 0
								11000 4150 2500 0 0
								11000 4330 2100 0 0
								11000 4330 2000 0 0
								11000 4330 1500 0 0
								11000 4560 1200 0 0
								11000 4560 1000 0 0
								11000 4570 700 1 0>;
				strategy_temp_normal_low =	<11000 4560 3000 0 0
								11000 4560 2500 0 0
								11000 4560 2000 0 0
								11000 4570 1800 1 0>;
				strategy_temp_normal_high =	<11000 4560 3000 0 0
								11000 4560 2500 0 0
								11000 4570 2000 1 0>;
				strategy_temp_warm =		<11000 4120 1500 0 0
								11000 4120 1000 0 0
								11000 4130 700 1 0>;
			};
			strategy_soc_range_low {
				strategy_temp_little_cold =	<11000 4150 1200 0 0
								11000 4150 1000 0 0
								11000 4570 700 1 0>;
				strategy_temp_cool =		<11000 4150 2100 0 0
								 11000 4150 2000 0 0
								11000 4150 1500 0 0
								11000 4510 1200 0 0
								11000 4510 1000 0 0
								11000 4570 700 1 0>;
				strategy_temp_little_cool =	<11000 4150 2700 0 0
								11000 4150 2500 0 0
								11000 4330 2100 0 0
								11000 4330 2000 0 0
								11000 4330 1500 0 0
								11000 4560 1200 0 0
								11000 4560 1000 0 0
								11000 4570 700 1 0>;
				strategy_temp_little_cool_high =	<11000 4150 2700 0 0
								11000 4150 2500 0 0
								11000 4330 2100 0 0
								11000 4330 2000 0 0
								11000 4330 1500 0 0
								11000 4560 1200 0 0
								11000 4560 1000 0 0
								11000 4570 700 1 0>;
				strategy_temp_normal_low =	<11000 4560 3000 0 0
								11000 4560 2500 0 0
								11000 4560 2000 0 0
								11000 4570 1800 1 0>;
				strategy_temp_normal_high =	<11000 4560 3000 0 0
								11000 4560 2500 0 0
								11000 4570 2000 1 0>;
				strategy_temp_warm =		<11000 4120 1500 0 0
								11000 4120 1000 0 0
								11000 4130 700 1 0>;
			};
			strategy_soc_range_mid_low {
				strategy_temp_little_cold =	<11000 4150 1000 0 0
								11000 4570 700 1 0>;
				strategy_temp_cool =		<11000 4150 2000 0 0
								11000 4150 1500 0 0
								11000 4510 1200 0 0
								11000 4510 1000 0 0
								11000 4570 700 1 0>;
				strategy_temp_little_cool =	<11000 4150 2700 0 0
								11000 4150 2500 0 0
								11000 4330 2100 0 0
								11000 4330 2000 0 0
								11000 4330 1500 0 0
								11000 4560 1200 0 0
								11000 4560 1000 0 0
								11000 4570 700 1 0>;
				strategy_temp_little_cool_high =	<11000 4150 2700 0 0
								11000 4150 2500 0 0
								11000 4330 2100 0 0
								11000 4330 2000 0 0
								11000 4330 1500 0 0
								11000 4560 1200 0 0
								11000 4560 1000 0 0
								11000 4570 700 1 0>;
				strategy_temp_normal_low =	<11000 4560 3000 0 0
								11000 4560 2500 0 0
								11000 4560 2000 0 0
								11000 4570 1800 1 0>;
				strategy_temp_normal_high =	<11000 4560 3000 0 0
								11000 4560 2500 0 0
								11000 4570 2000 1 0>;
				strategy_temp_warm =		<11000 4120 1500 0 0
								11000 4120 1000 0 0
								11000 4130 700 1 0>;
			};
			strategy_soc_range_mid {
				strategy_temp_little_cold =	<11000 4150 1000 0 0
								11000 4570 700 1 0>;
				strategy_temp_cool =		<11000 4150 2000 0 0
								11000 4150 1500 0 0
								11000 4510 1200 0 0
								11000 4510 1000 0 0
								11000 4570 700 1 0>;
				strategy_temp_little_cool =	<11000 4150 2700 0 0
								11000 4150 2500 0 0
								11000 4330 2100 0 0
								11000 4330 2000 0 0
								11000 4330 1500 0 0
								11000 4560 1200 0 0
								11000 4560 1000 0 0
								11000 4570 700 1 0>;
				strategy_temp_little_cool_high =	<11000 4150 2700 0 0
								11000 4150 2500 0 0
								11000 4330 2100 0 0
								11000 4330 2000 0 0
								11000 4330 1500 0 0
								11000 4560 1200 0 0
								11000 4560 1000 0 0
								11000 4570 700 1 0>;
				strategy_temp_normal_low =	<11000 4560 3000 0 0
								11000 4560 2500 0 0
								11000 4560 2000 0 0
								11000 4570 1800 1 0>;
				strategy_temp_normal_high =	<11000 4560 3000 0 0
								11000 4560 2500 0 0
								11000 4570 2000 1 0>;
				strategy_temp_warm =		<11000 4120 1500 0 0
								11000 4120 1000 0 0
								11000 4130 700 1 0>;
			};
			strategy_soc_range_mid_high {
				strategy_temp_little_cold =	<11000 4150 1000 0 0
								11000 4570 700 1 0>;
				strategy_temp_cool =		<11000 4150 2000 0 0
								11000 4150 1500 0 0
								11000 4510 1200 0 0
								11000 4510 1000 0 0
								11000 4570 700 1 0>;
				strategy_temp_little_cool =	<11000 4150 2700 0 0
								11000 4150 2500 0 0
								11000 4330 2100 0 0
								11000 4330 2000 0 0
								11000 4330 1500 0 0
								11000 4560 1200 0 0
								11000 4560 1000 0 0
								11000 4570 700 1 0>;
				strategy_temp_little_cool_high =	<11000 4150 2700 0 0
								11000 4150 2500 0 0
								11000 4330 2100 0 0
								11000 4330 2000 0 0
								11000 4330 1500 0 0
								11000 4560 1200 0 0
								11000 4560 1000 0 0
								11000 4570 700 1 0>;
				strategy_temp_normal_low =	<11000 4560 3000 0 0
								11000 4560 2500 0 0
								11000 4560 2000 0 0
								11000 4570 1800 1 0>;
				strategy_temp_normal_high =	<11000 4560 3000 0 0
								11000 4560 2500 0 0
								11000 4570 2000 1 0>;
				strategy_temp_warm =		<11000 4120 1500 0 0
								11000 4120 1000 0 0
								11000 4130 700 1 0>;
			};
			strategy_soc_range_high {
				strategy_temp_little_cold =	<11000 4150 1000 0 0
								11000 4570 700 1 0>;
				strategy_temp_cool =		<11000 4150 1500 0 0
								11000 4510 1200 0 0
								11000 4510 1000 0 0
								11000 4570 700 1 0>;
				strategy_temp_little_cool =	<11000 4330 1500 0 0
								11000 4560 1200 0 0
								11000 4560 1000 0 0
								11000 4570 700 1 0>;
				strategy_temp_little_cool_high =	<11000 4330 1500 0 0
								11000 4560 1200 0 0
								11000 4560 1000 0 0
								11000 4570 700 1 0>;
				strategy_temp_normal_low =	<11000 4560 2000 0 0
								11000 4570 1800 1 0>;
				strategy_temp_normal_high =	<11000 4570 2000 1 0>;
				strategy_temp_warm =		<11000 4120 1500 0 0
								11000 4120 1000 0 0
								11000 4130 700 1 0>;
			};
		};
	};
};
